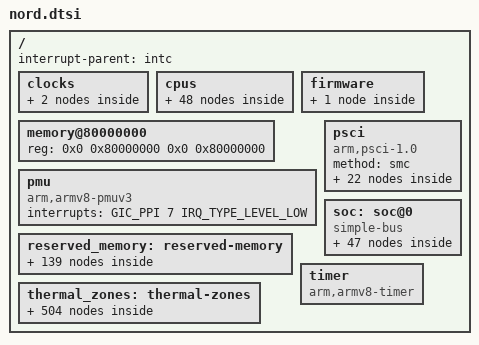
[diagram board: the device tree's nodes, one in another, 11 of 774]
// SPDX-License-Identifier: BSD-3-Clause
/*
 * Copyright (c) Qualcomm Technologies, Inc. and/or its subsidiaries.
 */

#include <dt-bindings/interrupt-controller/arm-gic.h>
#include <dt-bindings/mailbox/qcom-ipcc.h>
#include <dt-bindings/gpio/gpio.h>
/ {

	interrupt-parent = <&intc>;

	#address-cells = <2>;
	#size-cells = <2>;

	clocks {
		xo_board_clk: xo-board-clk {
			compatible = "fixed-clock";
			clock-frequency = <19200000>;
			#clock-cells = <0>;
		};

		sleep_clk: sleep-clk {
			compatible = "fixed-clock";
			clock-frequency = <32768>;
			#clock-cells = <0>;
		};
	};

	cpus {
		#address-cells = <2>;
		#size-cells = <0>;

		cpu0: cpu@0 {
			device_type = "cpu";
			compatible = "arm,armv8";
			reg = <0x0 0x0>;
			enable-method = "psci";
			power-domains = <&cpu_pd0>;
			power-domain-names = "psci";
			next-level-cache = <&l2_0>;
			clocks = <&cpu_perf 0>;
			l2_0: l2-cache {
				compatible = "cache";
				cache-level = <2>;
				cache-unified;
			};

		};

		cpu1: cpu@100 {
			device_type = "cpu";
			compatible = "arm,armv8";
			reg = <0x0 0x100>;
			enable-method = "psci";
			power-domains = <&cpu_pd1>;
			power-domain-names = "psci";
			next-level-cache = <&l2_0>;
			clocks = <&cpu_perf 0>;
		};

		cpu2: cpu@200 {
			device_type = "cpu";
			compatible = "arm,armv8";
			reg = <0x0 0x200>;
			enable-method = "psci";
			power-domains = <&cpu_pd2>;
			power-domain-names = "psci";
			next-level-cache = <&l2_0>;
			clocks = <&cpu_perf 0>;
		};

		cpu3: cpu@300 {
			device_type = "cpu";
			compatible = "arm,armv8";
			reg = <0x0 0x300>;
			enable-method = "psci";
			power-domains = <&cpu_pd3>;
			power-domain-names = "psci";
			next-level-cache = <&l2_0>;
			clocks = <&cpu_perf 0>;
		};

		cpu4: cpu@400 {
			device_type = "cpu";
			compatible = "arm,armv8";
			reg = <0x0 0x400>;
			enable-method = "psci";
			power-domains = <&cpu_pd4>;
			power-domain-names = "psci";
			next-level-cache = <&l2_0>;
			clocks = <&cpu_perf 0>;
		};

		cpu5: cpu@500 {
			device_type = "cpu";
			compatible = "arm,armv8";
			reg = <0x0 0x500>;
			enable-method = "psci";
			power-domains = <&cpu_pd5>;
			power-domain-names = "psci";
			next-level-cache = <&l2_0>;
			clocks = <&cpu_perf 0>;
		};

		cpu6: cpu@10000 {
			device_type = "cpu";
			compatible = "arm,armv8";
			reg = <0x0 0x10000>;
			power-domains = <&cpu_pd6>;
			power-domain-names = "psci";
			enable-method = "psci";
			next-level-cache = <&l2_10000>;
			clocks = <&cpu_perf 1>;
			l2_10000: l2-cache {
				compatible = "cache";
				cache-level = <2>;
				cache-unified;
			};
		};

		cpu7: cpu@10100 {
			device_type = "cpu";
			compatible = "arm,armv8";
			reg = <0x0 0x10100>;
			enable-method = "psci";
			power-domains = <&cpu_pd7>;
			power-domain-names = "psci";
			next-level-cache = <&l2_10000>;
			clocks = <&cpu_perf 1>;
		};

		cpu8: cpu@10200 {
			device_type = "cpu";
			compatible = "arm,armv8";
			reg = <0x0 0x10200>;
			enable-method = "psci";
			power-domains = <&cpu_pd8>;
			power-domain-names = "psci";
			next-level-cache = <&l2_10000>;
			clocks = <&cpu_perf 1>;
		};

		cpu9: cpu@10300 {
			device_type = "cpu";
			compatible = "arm,armv8";
			reg = <0x0 0x10300>;
			enable-method = "psci";
			power-domains = <&cpu_pd9>;
			power-domain-names = "psci";
			next-level-cache = <&l2_10000>;
			clocks = <&cpu_perf 1>;
		};

		cpu10: cpu@10400 {
			device_type = "cpu";
			compatible = "arm,armv8";
			reg = <0x0 0x10400>;
			enable-method = "psci";
			power-domains = <&cpu_pd10>;
			power-domain-names = "psci";
			next-level-cache = <&l2_10000>;
			clocks = <&cpu_perf 1>;
		};

		cpu11: cpu@10500 {
			device_type = "cpu";
			compatible = "arm,armv8";
			reg = <0x0 0x10500>;
			enable-method = "psci";
			power-domains = <&cpu_pd11>;
			power-domain-names = "psci";
			next-level-cache = <&l2_10000>;
			clocks = <&cpu_perf 1>;
		};

		cpu12: cpu@20000 {
			device_type = "cpu";
			compatible = "arm,armv8";
			reg = <0x0 0x20000>;
			enable-method = "psci";
			power-domains = <&cpu_pd12>;
			power-domain-names = "psci";
			next-level-cache = <&l2_20000>;
			clocks = <&cpu_perf 2>;
			l2_20000: l2-cache {
				compatible = "cache";
				cache-level = <2>;
				cache-unified;
			};
		};

		cpu13: cpu@20100 {
			device_type = "cpu";
			compatible = "arm,armv8";
			reg = <0x0 0x20100>;
			enable-method = "psci";
			power-domains = <&cpu_pd13>;
			power-domain-names = "psci";
			next-level-cache = <&l2_20000>;
			clocks = <&cpu_perf 2>;
		};

		cpu14: cpu@20200 {
			device_type = "cpu";
			compatible = "arm,armv8";
			reg = <0x0 0x20200>;
			enable-method = "psci";
			power-domains = <&cpu_pd14>;
			power-domain-names = "psci";
			next-level-cache = <&l2_20000>;
			clocks = <&cpu_perf 2>;
		};

		cpu15: cpu@20300 {
			device_type = "cpu";
			compatible = "arm,armv8";
			reg = <0x0 0x20300>;
			enable-method = "psci";
			power-domains = <&cpu_pd15>;
			power-domain-names = "psci";
			next-level-cache = <&l2_20000>;
			clocks = <&cpu_perf 2>;
		};

		cpu16: cpu@20400 {
			device_type = "cpu";
			compatible = "arm,armv8";
			reg = <0x0 0x20400>;
			enable-method = "psci";
			power-domains = <&cpu_pd16>;
			power-domain-names = "psci";
			next-level-cache = <&l2_20000>;
			clocks = <&cpu_perf 2>;
		};

		cpu17: cpu@20500 {
			device_type = "cpu";
			compatible = "arm,armv8";
			reg = <0x0 0x20500>;
			enable-method = "psci";
			power-domains = <&cpu_pd17>;
			power-domain-names = "psci";
			next-level-cache = <&l2_20000>;
			clocks = <&cpu_perf 2>;
		};

		cpu-map {
			cluster0 {
				core0 {
					cpu = <&cpu0>;
				};

				core1 {
					cpu = <&cpu1>;
				};

				core2 {
					cpu = <&cpu2>;
				};

				core3 {
					cpu = <&cpu3>;
				};

				core4 {
					cpu = <&cpu4>;
				};

				core5 {
					cpu = <&cpu5>;
				};
			};

			cluster1 {
				core0 {
					cpu = <&cpu6>;
				};

				core1 {
					cpu = <&cpu7>;
				};

				core2 {
					cpu = <&cpu8>;
				};

				core3 {
					cpu = <&cpu9>;
				};

				core4 {
					cpu = <&cpu10>;
				};

				core5 {
					cpu = <&cpu11>;
				};
			};

			cluster2 {
				core0 {
					cpu = <&cpu12>;
				};

				core1 {
					cpu = <&cpu13>;
				};

				core2 {
					cpu = <&cpu14>;
				};

				core3 {
					cpu = <&cpu15>;
				};

				core4 {
					cpu = <&cpu16>;
				};

				core5 {
					cpu = <&cpu17>;
				};
			};
		};

		idle-states {
			entry-method = "psci";

			cpu_c4: cpu-sleep { /* C4 */
				compatible = "arm,idle-state";
				idle-state-name = "ret";
				arm,psci-suspend-param = <0x00000003>;
				entry-latency-us = <93>;
				exit-latency-us = <129>;
				min-residency-us = <560>;				
			};
		};

		domain-idle-states {
			cluster_pwr_dn: cluster-sleep-0 {
				compatible = "domain-idle-state";
				arm,psci-suspend-param = <0x01000053>;
				entry-latency-us = <2150>;
				exit-latency-us = <1983>;
				min-residency-us = <9144>;
			};

			domain_ss3: domain-sleep-0 {
				compatible = "domain-idle-state";
				arm,psci-suspend-param = <0x0200c353>;
				entry-latency-us = <2800>;
				exit-latency-us = <4400>;
				min-residency-us = <10150>;
			};
		};
	};

	firmware: firmware {
		scm {
			compatible = "qcom,scm-nord", "qcom,scm";
			qcom,dload-mode = <&tcsr 0x79000>;
		};
	};

	memory@80000000 {
		device_type = "memory";
		reg = <0x0 0x80000000 0x0 0x80000000>;
	};

	pmu {
		compatible = "arm,armv8-pmuv3";
		interrupts = <GIC_PPI 7 IRQ_TYPE_LEVEL_LOW>;
	};

	psci {
		compatible = "arm,psci-1.0";
		method = "smc";

		cpu_pd0: power-domain-cpu0 {
			#power-domain-cells = <0>;
			power-domains = <&cluster0_pd>;
			domain-idle-states = <&cpu_c4>;
		};

		cpu_pd1: power-domain-cpu1 {
			#power-domain-cells = <0>;
			power-domains = <&cluster0_pd>;
			domain-idle-states = <&cpu_c4>;
		};

		cpu_pd2: power-domain-cpu2 {
			#power-domain-cells = <0>;
			power-domains = <&cluster0_pd>;
			domain-idle-states = <&cpu_c4>;
		};

		cpu_pd3: power-domain-cpu3 {
			#power-domain-cells = <0>;
			power-domains = <&cluster0_pd>;
			domain-idle-states = <&cpu_c4>;
		};

		cpu_pd4: power-domain-cpu4 {
			#power-domain-cells = <0>;
			power-domains = <&cluster0_pd>;
			domain-idle-states = <&cpu_c4>;
		};

		cpu_pd5: power-domain-cpu5 {
			#power-domain-cells = <0>;
			power-domains = <&cluster0_pd>;
			domain-idle-states = <&cpu_c4>;
		};

		cpu_pd6: power-domain-cpu6 {
			#power-domain-cells = <0>;
			power-domains = <&cluster1_pd>;
			domain-idle-states = <&cpu_c4>;
		};

		cpu_pd7: power-domain-cpu7 {
			#power-domain-cells = <0>;
			power-domains = <&cluster1_pd>;
			domain-idle-states = <&cpu_c4>;
		};

		cpu_pd8: power-domain-cpu8 {
			#power-domain-cells = <0>;
			power-domains = <&cluster1_pd>;
			domain-idle-states = <&cpu_c4>;
		};

		cpu_pd9: power-domain-cpu9 {
			#power-domain-cells = <0>;
			power-domains = <&cluster1_pd>;
			domain-idle-states = <&cpu_c4>;
		};

		cpu_pd10: power-domain-cpu10 {
			#power-domain-cells = <0>;
			power-domains = <&cluster1_pd>;
			domain-idle-states = <&cpu_c4>;
		};

		cpu_pd11: power-domain-cpu11 {
			#power-domain-cells = <0>;
			power-domains = <&cluster1_pd>;
			domain-idle-states = <&cpu_c4>;
		};

		cpu_pd12: power-domain-cpu12 {
			#power-domain-cells = <0>;
			power-domains = <&cluster2_pd>;
			domain-idle-states = <&cpu_c4>;
		};

		cpu_pd13: power-domain-cpu13 {
			#power-domain-cells = <0>;
			power-domains = <&cluster2_pd>;
			domain-idle-states = <&cpu_c4>;
		};

		cpu_pd14: power-domain-cpu14 {
			#power-domain-cells = <0>;
			power-domains = <&cluster2_pd>;
			domain-idle-states = <&cpu_c4>;
		};

		cpu_pd15: power-domain-cpu15 {
			#power-domain-cells = <0>;
			power-domains = <&cluster2_pd>;
			domain-idle-states = <&cpu_c4>;
		};

		cpu_pd16: power-domain-cpu16 {
			#power-domain-cells = <0>;
			power-domains = <&cluster2_pd>;
			domain-idle-states = <&cpu_c4>;
		};

		cpu_pd17: power-domain-cpu17 {
			#power-domain-cells = <0>;
			power-domains = <&cluster2_pd>;
			domain-idle-states = <&cpu_c4>;
		};

		cluster0_pd: power-domain-cluster0 {
			#power-domain-cells = <0>;
			power-domains = <&system_pd>;
			domain-idle-states = <&cluster_pwr_dn>;
		};

		cluster1_pd: power-domain-cluster1 {
			#power-domain-cells = <0>;
			power-domains = <&system_pd>;
			domain-idle-states = <&cluster_pwr_dn>;
		};

		cluster2_pd: power-domain-cluster2 {
			#power-domain-cells = <0>;
			power-domains = <&system_pd>;
			domain-idle-states = <&cluster_pwr_dn>;
		};

		system_pd: power-domain-cluster3 {
			#power-domain-cells = <0>;
			domain-idle-states = <&domain_ss3>;
		};
	};

	reserved_memory: reserved-memory {
		#address-cells = <2>;
		#size-cells = <2>;
		ranges;

		cpucp_scandump_mem: cpucp_scandump_region@80000000 {
			no-map;
			reg = <0x0 0x80000000 0x0 0x800000>;
		};

		tme_sail_mem: tme_sail_region@81ff0000 {
			no-map;
			reg = <0x0 0x81ff0000 0x0 0x10000>;
		};

		tz_sail_mailbox_mem: tz_sail_mailbox_region@82000000 {
			no-map;
			reg = <0x0 0x82000000 0x0 0x8000>;
		};

		hlos_sail_mailbox_mem: hlos_sail_mailbox_region@82008000 {
			no-map;
			reg = <0x0 0x82008000 0x0 0x1f8000>;
		};

		sail_ota_mem: sail_ota_region@82200000 {
			no-map;
			reg = <0x0 0x82200000 0x0 0x5ff000>;
		};

		sail_vdt_mem: sail_vdt_region@827ff000 {
			no-map;
			reg = <0x0 0x827ff000 0x0 0x1000>;
		};

		gunyah_hyp_mem: gunyah_hyp_region@82800000 {
			no-map;
			reg = <0x0 0x82800000 0x0 0x2400000>;
		};

		deepsleep_mem: deepsleep_region@84c00000 {
			no-map;
			reg = <0x0 0x84c00000 0x0 0x800000>;
		};

		deepsleep_backup_mem: deepsleep_backup_region@86a00000 {
			no-map;
			reg = <0x0 0x86a00000 0x0 0x200000>;
		};

		soccp_fe_vm_0: soccp_fe_vm_0_region@86c00000 {
			no-map;
			reg = <0x0 0x86c00000 0x0 0xac000>;
		};

		soccp_fe_vm_1: soccp_fe_vm_1_region@86cac000 {
			no-map;
			reg = <0x0 0x86cac000 0x0 0x18d000>;
		};

		soccp_fe_vm_2: soccp_fe_vm_2_region@86e39000 {
			no-map;
			reg = <0x0 0x86e39000 0x0 0x1c7000>;
		};

		tme_crash_dump_mem: tme_crash_dump_region@87000000 {
			no-map;
			reg = <0x0 0x87000000 0x0 0xa0000>;
		};

		tme_log_mem: tme_log_region@87140000 {
			no-map;
			reg = <0x0 0x87140000 0x0 0x4000>;
		};

		aop_cmd_db_p_mem: aop_cmd_db_p_region@87148000 {
			compatible = "qcom,cmd-db";
			no-map;
			reg = <0x0 0x87148000 0x0 0x20000>;
		};

		nsp_sync_buffer_mem: nsp_sync_buffer_region@871ff000 {
			no-map;
			reg = <0x0 0x871ff000 0x0 0x1000>;
		};

		ddr_training_checksum_data_mem: ddr_training_checksum_data_region@87200000 {
			no-map;
			reg = <0x0 0x87200000 0x0 0x2000>;
		};

		xbl_dtlog_mem: xbl_dtlog_region@87202000 {
			no-map;
			reg = <0x0 0x87202000 0x0 0x60000>;
		};

		xbl_ramdump_mem: xbl_ramdump_region@87262000 {
			no-map;
			reg = <0x0 0x87262000 0x0 0x1c0000>;
		};

		uefi_log: uefi-log@87442000 {
			reg = <0x0 0x87442000 0x0 0x10000>;
			no-map;
		};

		secdata_apss_mem: secdata_apss_region@87452000 {
			no-map;
			reg = <0x0 0x87452000 0x0 0x1000>;
		};

		antireplay_emulation_mem: antireplay_emulation_region@87453000 {
			no-map;
			reg = <0x0 0x87453000 0x0 0x1000>;
		};

		soccp_sdi_mem: soccp_sdi_region@87454000 {
			no-map;
			reg = <0x0 0x87454000 0x0 0x40000>;
		};

		hyp_mem_database_mem: hyp_mem_database_region@87494000 {
			no-map;
			reg = <0x0 0x87494000 0x0 0x60000>;
		};

		pmic_mini_dump_mem: pmic_mini_dump_region@874f4000 {
			no-map;
			reg = <0x0 0x874f4000 0x0 0x80000>;
		};

		qup_fw_mem: qup_fw_region@87574000 {
			no-map;
			reg = <0x0 0x87574000 0x0 0x20000>;
		};

		softsku_mem: softsku_region@87594000 {
			no-map;
			reg = <0x0 0x87594000 0x0 0x9000>;
		};

		resource_scheduler_mem: resource_scheduler_region@8759d000 {
			no-map;
			reg = <0x0 0x8759d000 0x0 0x20000>;
		};

		pdp_ns_mem: pdp_ns_mem_region@87600000 {
			no-map;
			reg = <0x0 0x87600000 0x0 0x200000>;
		};

		tz_stat_mem: tz_stat_region@87a00000 {
			no-map;
			reg = <0x0 0x87a00000 0x0 0x100000>;
		};

		qdss_apps_mem: qdss_apps_region@87b00000 {
			no-map;
			reg = <0x0 0x87b00000 0x0 0x2000000>;
		};

		smem_mem: smem_region@89b00000 {
			compatible = "qcom,smem";
			no-map;
			reg = <0x0 0x89b00000 0x0 0x400000>;
			hwlocks = <&tcsr_mutex 3>;
		};

		global_sync_mem: global_sync_region@89f00000 {
			no-map;
			reg = <0x0 0x89f00000 0x0 0x400000>;
		};

		tzffi_mem: tzffi_region@8a300000 {
			compatible = "shared-dma-pool";
			reg = <0x0 0x8a300000 0x0 0x1400000>;
			no-map;
		};

		gunyah_md_mem: gunyah_md_region@8b700000 {
			no-map;
			reg = <0x0 0x8b700000 0x0 0x80000>;
		};

		flashless_qntm_tool_mem: flashless_qntm_tool_region@8b780000 {
			no-map;
			reg = <0x0 0x8b780000 0x0 0x182000>;
		};

		ipa_fw_mem: ipa_fw_region@8bb00000 {
			no-map;
			reg = <0x0 0x8bb00000 0x0 0x10000>;
		};

		ipa_gsi_mem: ipa_gsi_region@8bb10000 {
			no-map;
			reg = <0x0 0x8bb10000 0x0 0xa000>;
		};

		gpu_microcode_mem: gpu_microcode_region@8bb1a000 {
			no-map;
			reg = <0x0 0x8bb1a000 0x0 0x2000>;
		};

		gpu_microcode_2_mem: gpu_microcode_2_region@8bb1c000 {
			no-map;
			reg = <0x0 0x8bb1c000 0x0 0x2000>;
		};

		soccp_mem: soccp_region@8bc00000 {
			no-map;
			reg = <0x0 0x8bc00000 0x0 0x300000>;
		};

		cvp_mem: cvp_region@8d100000 {
			no-map;
			reg = <0x0 0x8d100000 0x0 0x800000>;
		};

		cdsp0_mem: cdsp0_region@8d900000 {
			no-map;
			reg = <0x0 0x8d900000 0x0 0x2300000>;
		};

		cdsp1_mem: cdsp1_region@8fc00000 {
			no-map;
			reg = <0x0 0x8fc00000 0x0 0x2300000>;
		};

		cdsp2_mem: cdsp2_region@91f00000 {
			no-map;
			reg = <0x0 0x91f00000 0x0 0x2300000>;
		};

		cdsp3_mem: cdsp3_region@94200000 {
			no-map;
			reg = <0x0 0x94200000 0x0 0x2300000>;
		};

		hpass_dsp0_mem: hpass_dsp0_region@96500000 {
			no-map;
			reg = <0x0 0x96500000 0x0 0x2800000>;
		};

		hpass_dsp1_mem: hpass_dsp1_region@98d00000 {
			no-map;
			reg = <0x0 0x98d00000 0x0 0x2800000>;
		};

		hpass_dsp2_mem: hpass_dsp2_region@9b500000 {
			no-map;
			reg = <0x0 0x9b500000 0x0 0x2800000>;
		};

		q6_cdsp0_dtb_mem: q6_cdsp0_dtb_region@9dd00000 {
			no-map;
			reg = <0x0 0x9dd00000 0x0 0x80000>;
		};

		q6_cdsp1_dtb_mem: q6_cdsp1_dtb_region@9dd80000 {
			no-map;
			reg = <0x0 0x9dd80000 0x0 0x80000>;
		};

		q6_cdsp2_dtb_mem: q6_cdsp2_dtb_region@9de00000 {
			no-map;
			reg = <0x0 0x9de00000 0x0 0x80000>;
		};

		q6_cdsp3_dtb_mem: q6_cdsp3_dtb_region@9de80000 {
			no-map;
			reg = <0x0 0x9de80000 0x0 0x80000>;
		};

		hpass_dsp0_dtb_mem: hpass_dsp0_dtb_region@9df00000 {
			no-map;
			reg = <0x0 0x9df00000 0x0 0x80000>;
		};

		hpass_dsp1_dtb_mem: hpass_dsp1_dtb_region@9df80000 {
			no-map;
			reg = <0x0 0x9df80000 0x0 0x80000>;
		};

		hpass_dsp2_dtb_mem: hpass_dsp2_dtb_region@9e000000 {
			no-map;
			reg = <0x0 0x9e000000 0x0 0x100000>;
		};

		camera_icp_1_mem: camera_icp_1_region@9e100000 {
			no-map;
			reg = <0x0 0x9e100000 0x0 0x800000>;
		};

		camera_icp_2_mem: camera_icp_2_region@9e900000 {
			no-map;
			reg = <0x0 0x9e900000 0x0 0x800000>;
		};

		camera_qup_1_mem: camera_qup_1_region@9f100000 {
			no-map;
			reg = <0x0 0x9f100000 0x0 0x200000>;
		};

		camera_qup_2_mem: camera_qup_2_region@9f300000 {
			no-map;
			reg = <0x0 0x9f300000 0x0 0x200000>;
		};

		video_mem: video_region@9f500000 {
			no-map;
			reg = <0x0 0x9f500000 0x0 0xc00000>;
		};

		pil_umd_reserved: mdt_load_region@a0100000 {
			no-map;
			reg = <0x0 0xa0100000 0x0 0x100000>;
		};

		mm_dspq: mm_dspq_region@ba200000 {
			no-map;
			reg = <0x0 0xba200000 0x0 0x200000>;
		};

		display_config_reserved: display_config_region@ba400000 {
			no-map;
			reg = <0x0 0xba400000 0x0 0xa00000>;
		};

		mm_calibration_data_mem: mm_calibration_data_region@bae00000 {
			no-map;
			reg = <0x0 0xbae00000 0x0 0x800000>;
		};

		audio_config_mem: audio_config_region@bb600000 {
			no-map;
			reg = <0x0 0xbb600000 0x0 0xa00000>;
		};

		dare_tz_mem: dare_tz_region@bc000000 {
			no-map;
			reg = <0x0 0xbc000000 0x0 0xa300000>;
		};

		hpass_rpc_remote_heap_mem: hpass_rpc_remote_heap_region@d4600000 {
			no-map;
			reg = <0x0 0xd4600000 0x0 0x800000>;
		};

		mdf_mem: mdf_region@d4e00000 {
			no-map;
			reg = <0x0 0xd4e00000 0x0 0x2000000>;
		};

		gearvm_mem: gearvm_region@d6e00000 {
			no-map;
			reg = <0x0 0xd6e00000 0x0 0x800000>;
		};

		shmem0: scmi-sram@d7600000 {
			compatible = "arm,scmi-shmem";
			reg = <0x0 0xd7600000 0x0 0x1000>;
			no-map;
		};

		shmem1: scmi-sram@d7601000 {
			compatible = "arm,scmi-shmem";
			reg = <0x0 0xd7601000 0x0 0x1000>;
			no-map;
		};

		shmem2: scmi-sram@d7602000 {
			compatible = "arm,scmi-shmem";
			reg = <0x0 0xd7602000 0x0 0x1000>;
			no-map;
		};

		shmem3: scmi-sram@d7603000 {
			compatible = "arm,scmi-shmem";
			reg = <0x0 0xd7603000 0x0 0x1000>;
			no-map;
		};

		shmem4: scmi-sram@d7604000 {
			compatible = "arm,scmi-shmem";
			reg = <0x0 0xd7604000 0x0 0x1000>;
			no-map;
		};

		shmem5: scmi-sram@d7605000 {
			compatible = "arm,scmi-shmem";
			reg = <0x0 0xd7605000 0x0 0x1000>;
			no-map;
		};

		shmem6: scmi-sram@d7606000 {
			compatible = "arm,scmi-shmem";
			reg = <0x0 0xd7606000 0x0 0x1000>;
			no-map;
		};

		shmem7: scmi-sram@d7607000 {
			compatible = "arm,scmi-shmem";
			reg = <0x0 0xd7607000 0x0 0x1000>;
			no-map;
		};

		shmem8: scmi-sram@d7608000 {
			compatible = "arm,scmi-shmem";
			reg = <0x0 0xd7608000 0x0 0x1000>;
			no-map;
		};

		shmem9: scmi-sram@d7609000 {
			compatible = "arm,scmi-shmem";
			reg = <0x0 0xd7609000 0x0 0x1000>;
			no-map;
		};

		shmem10: scmi-sram@d760a000 {
			compatible = "arm,scmi-shmem";
			reg = <0x0 0xd760a000 0x0 0x1000>;
			no-map;
		};

		shmem11: scmi-sram@d760b000 {
			compatible = "arm,scmi-shmem";
			reg = <0x0 0xd760b000 0x0 0x1000>;
			no-map;
		};

		shmem12: scmi-sram@d760c000 {
			compatible = "arm,scmi-shmem";
			reg = <0x0 0xd760c000 0x0 0x1000>;
			no-map;
		};

		shmem13: scmi-sram@d760d000 {
			compatible = "arm,scmi-shmem";
			reg = <0x0 0xd760d000 0x0 0x1000>;
			no-map;
		};

		shmem14: scmi-sram@d760e000 {
			compatible = "arm,scmi-shmem";
			reg = <0x0 0xd760e000 0x0 0x1000>;
			no-map;
		};

		shmem15: scmi-sram@d760f000 {
			compatible = "arm,scmi-shmem";
			reg = <0x0 0xd760f000 0x0 0x1000>;
			no-map;
		};

		shmem16: scmi-sram@d7610000 {
			compatible = "arm,scmi-shmem";
			reg = <0x0 0xd7610000 0x0 0x1000>;
			no-map;
		};

		shmem17: scmi-sram@d7611000 {
			compatible = "arm,scmi-shmem";
			reg = <0x0 0xd7611000 0x0 0x1000>;
			no-map;
		};

		shmem18: scmi-sram@d7612000 {
			compatible = "arm,scmi-shmem";
			reg = <0x0 0xd7612000 0x0 0x1000>;
			no-map;
		};

		shmem19: scmi-sram@d7613000 {
			compatible = "arm,scmi-shmem";
			reg = <0x0 0xd7613000 0x0 0x1000>;
			no-map;
		};

		shmem20: scmi-sram@d7614000 {
			compatible = "arm,scmi-shmem";
			reg = <0x0 0xd7614000 0x0 0x1000>;
			no-map;
		};

		shmem21: scmi-sram@d7615000 {
			compatible = "arm,scmi-shmem";
			reg = <0x0 0xd7615000 0x0 0x1000>;
			no-map;
		};

		shmem22: scmi-sram@d7616000 {
			compatible = "arm,scmi-shmem";
			reg = <0x0 0xd7616000 0x0 0x1000>;
			no-map;
		};

		shmem23: scmi-sram@d7617000 {
			compatible = "arm,scmi-shmem";
			reg = <0x0 0xd7617000 0x0 0x1000>;
			no-map;
		};

		shmem24: scmi-sram@d7618000 {
			compatible = "arm,scmi-shmem";
			reg = <0x0 0xd7618000 0x0 0x1000>;
			no-map;
		};

		shmem25: scmi-sram@d7619000 {
			compatible = "arm,scmi-shmem";
			reg = <0x0 0xd7619000 0x0 0x1000>;
			no-map;
		};

		shmem26: scmi-sram@d761a000 {
			compatible = "arm,scmi-shmem";
			reg = <0x0 0xd761a000 0x0 0x1000>;
			no-map;
		};

		shmem27: scmi-sram@d761b000 {
			compatible = "arm,scmi-shmem";
			reg = <0x0 0xd761b000 0x0 0x1000>;
			no-map;
		};

		shmem28: scmi-sram@d761c000 {
			compatible = "arm,scmi-shmem";
			reg = <0x0 0xd761c000 0x0 0x1000>;
			no-map;
		};

		shmem29: scmi-sram@d761d000 {
			compatible = "arm,scmi-shmem";
			reg = <0x0 0xd761d000 0x0 0x1000>;
			no-map;
		};

		shmem30: scmi-sram@d761e000 {
			compatible = "arm,scmi-shmem";
			reg = <0x0 0xd761e000 0x0 0x1000>;
			no-map;
		};

		shmem31: scmi-sram@d761f000 {
			compatible = "arm,scmi-shmem";
			reg = <0x0 0xd761f000 0x0 0x1000>;
			no-map;
		};

		shmem32: scmi-sram@d7620000 {
			compatible = "arm,scmi-shmem";
			reg = <0x0 0xd7620000 0x0 0x1000>;
			no-map;
		};

		shmem33: scmi-sram@d7621000 {
			compatible = "arm,scmi-shmem";
			reg = <0x0 0xd7621000 0x0 0x1000>;
			no-map;
		};

		shmem34: scmi-sram@d7622000 {
			compatible = "arm,scmi-shmem";
			reg = <0x0 0xd7622000 0x0 0x1000>;
			no-map;
		};

		shmem35: scmi-sram@d7623000 {
			compatible = "arm,scmi-shmem";
			reg = <0x0 0xd7623000 0x0 0x1000>;
			no-map;
		};

		shmem36: scmi-sram@d7624000 {
			compatible = "arm,scmi-shmem";
			reg = <0x0 0xd7624000 0x0 0x1000>;
			no-map;
		};

		shmem37: scmi-sram@d7625000 {
			compatible = "arm,scmi-shmem";
			reg = <0x0 0xd7625000 0x0 0x1000>;
			no-map;
		};

		shmem38: scmi-sram@d7626000 {
			compatible = "arm,scmi-shmem";
			reg = <0x0 0xd7626000 0x0 0x1000>;
			no-map;
		};

		shmem39: scmi-sram@d7627000 {
			compatible = "arm,scmi-shmem";
			reg = <0x0 0xd7627000 0x0 0x1000>;
			no-map;
		};

		shmem40: scmi-sram@d7628000 {
			compatible = "arm,scmi-shmem";
			reg = <0x0 0xd7628000 0x0 0x1000>;
			no-map;
		};

		shmem41: scmi-sram@d7629000 {
			compatible = "arm,scmi-shmem";
			reg = <0x0 0xd7629000 0x0 0x1000>;
			no-map;
		};

		shmem42: scmi-sram@d762a000 {
			compatible = "arm,scmi-shmem";
			reg = <0x0 0xd762a000 0x0 0x1000>;
			no-map;
		};

		shmem43: scmi-sram@d762b000 {
			compatible = "arm,scmi-shmem";
			reg = <0x0 0xd762b000 0x0 0x1000>;
			no-map;
		};

		shmem44: scmi-sram@d762c000 {
			compatible = "arm,scmi-shmem";
			reg = <0x0 0xd762c000 0x0 0x1000>;
			no-map;
		};

		shmem45: scmi-sram@d762d000 {
			compatible = "arm,scmi-shmem";
			reg = <0x0 0xd762d000 0x0 0x1000>;
			no-map;
		};

		shmem46: scmi-sram@d762e000 {
			compatible = "arm,scmi-shmem";
			reg = <0x0 0xd762e000 0x0 0x1000>;
			no-map;
		};

		shmem47: scmi-sram@d762f000 {
			compatible = "arm,scmi-shmem";
			reg = <0x0 0xd762f000 0x0 0x1000>;
			no-map;
		};

		shmem48: scmi-sram@d7630000 {
			compatible = "arm,scmi-shmem";
			reg = <0x0 0xd7630000 0x0 0x1000>;
			no-map;
		};

		shmem49: scmi-sram@d7631000 {
			compatible = "arm,scmi-shmem";
			reg = <0x0 0xd7631000 0x0 0x1000>;
			no-map;
		};

		shmem50: scmi-sram@d7632000 {
			compatible = "arm,scmi-shmem";
			reg = <0x0 0xd7632000 0x0 0x1000>;
			no-map;
		};

		shmem51: scmi-sram@d7633000 {
			compatible = "arm,scmi-shmem";
			reg = <0x0 0xd7633000 0x0 0x1000>;
			no-map;
		};

		shmem52: scmi-sram@d7634000 {
			compatible = "arm,scmi-shmem";
			reg = <0x0 0xd7634000 0x0 0x1000>;
			no-map;
		};

		shmem53: scmi-sram@d7635000 {
			compatible = "arm,scmi-shmem";
			reg = <0x0 0xd7635000 0x0 0x1000>;
			no-map;
		};

		shmem54: scmi-sram@d7636000 {
			compatible = "arm,scmi-shmem";
			reg = <0x0 0xd7636000 0x0 0x1000>;
			no-map;
		};

		shmem55: scmi-sram@d7637000 {
			compatible = "arm,scmi-shmem";
			reg = <0x0 0xd7637000 0x0 0x1000>;
			no-map;
		};

		shmem56: scmi-sram@d7638000 {
			compatible = "arm,scmi-shmem";
			reg = <0x0 0xd7638000 0x0 0x1000>;
			no-map;
		};

		shmem57: scmi-sram@d7639000 {
			compatible = "arm,scmi-shmem";
			reg = <0x0 0xd7639000 0x0 0x1000>;
			no-map;
		};

		shmem58: scmi-sram@d763a000 {
			compatible = "arm,scmi-shmem";
			reg = <0x0 0xd763a000 0x0 0x1000>;
			no-map;
		};

		shmem59: scmi-sram@d763b000 {
			compatible = "arm,scmi-shmem";
			reg = <0x0 0xd763b000 0x0 0x1000>;
			no-map;
		};

		shmem60: scmi-sram@d763c000 {
			compatible = "arm,scmi-shmem";
			reg = <0x0 0xd763c000 0x0 0x1000>;
			no-map;
		};

		shmem61: scmi-sram@d763d000 {
			compatible = "arm,scmi-shmem";
			reg = <0x0 0xd763d000 0x0 0x1000>;
			no-map;
		};

		shmem62: scmi-sram@d763e000 {
			compatible = "arm,scmi-shmem";
			reg = <0x0 0xd763e000 0x0 0x1000>;
			no-map;
		};

		shmem63: scmi-sram@d763f000 {
			compatible = "arm,scmi-shmem";
			reg = <0x0 0xd763f000 0x0 0x1000>;
			no-map;
		};

		gearvm_logs_mem: gearvm_logs_region@d77d0000 {
			no-map;
			reg = <0x0 0xd77d0000 0x0 0x20000>;
		};

		gearvm_shared_mem: gearvm_shared_region@d7650000 {
			no-map;
			reg = <0x0 0xd7650000 0x0 0x1b0000>;
		};

		sail_p_mem: sail_p_region@8c0000000 {
			no-map;
			reg = <0x8 0xc0000000 0x0 0x8000000>;
		};

		reserved_mem2: reserved_region@8c8000000 {
			no-map;
			reg = <0x8 0xc8000000 0x0 0x18000000>;
		};

		dump_mem: mem-dump-region {
			alloc-ranges = <0x0 0x00000000 0x0 0xffffffff>;
			size = <0x0 0x79b0000>;
		};
	};

	soc: soc@0 {
		compatible = "simple-bus";
		#address-cells = <2>;
		#size-cells = <2>;
		ranges = <0 0 0 0 0x10 0>;

		qupv3_id_2: geniqup@8c0000 {
			compatible = "qcom,nord-auto-geni-se-qup","qcom,sa8255p-geni-se-qup";
			reg = <0x0 0x8c0000 0x0 0x2000>;
			#address-cells = <2>;
			#size-cells = <2>;
			iommus = <&apps_smmu_0 0x15a3 0x0>;
			ranges;

			uart15: serial@884000 {
				compatible = "qcom,nord-auto-geni-debug-uart","qcom,sa8255p-geni-debug-uart";
				reg = <0x0 0x884000 0x0 0x4000>;
				interrupts = <GIC_SPI 583 IRQ_TYPE_LEVEL_HIGH>;
				power-domains = <&scmi11_pd 15>, <&scmi11_dvfs 15>;
				power-domain-names = "power", "perf";
				status = "disabled";
			};

			uart17: serial@88c000 {
				compatible = "qcom,nord-auto-geni-uart","qcom,sa8255p-geni-uart";
				reg = <0x0 0x88c000 0x0 0x4000>;
				interrupts = <GIC_SPI 585 IRQ_TYPE_LEVEL_HIGH>;
				power-domains = <&scmi11_pd 17>, <&scmi11_dvfs 17>;
				power-domain-names = "power", "perf";
				qcom,wakeup-byte = <0xfd>;
				status = "disabled";
			};
		};

		qupv3_id_0: geniqup@9c0000 {
			compatible = "qcom,nord-auto-geni-se-qup","qcom,sa8255p-geni-se-qup";
			reg = <0x0 0x9c0000 0x0 0x2000>;
			#address-cells = <2>;
			#size-cells = <2>;
			iommus = <&apps_smmu_2 0x1003 0x0>;
			ranges;

			uart3: serial@98c000 {
				compatible = "qcom,nord-auto-geni-uart","qcom,sa8255p-geni-uart";
				reg = <0x0 0x98c000 0x0 0x4000>;
				interrupts = <GIC_SPI 515 IRQ_TYPE_LEVEL_HIGH>;
				power-domains = <&scmi11_pd 3>, <&scmi11_dvfs 3>;
				power-domain-names = "power", "perf";
				qcom,wakeup-byte = <0xfd>;
				status = "disabled";
			};

			uart0: serial@980000 {
				compatible = "qcom,nord-auto-geni-uart","qcom,sa8255p-geni-uart";
				reg = <0x0 0x980000 0x0 0x4000>;
				interrupts = <GIC_SPI 314 IRQ_TYPE_LEVEL_HIGH>;
				power-domains = <&scmi11_pd 0>, <&scmi11_dvfs 0>;
				power-domain-names = "power", "perf";
				status = "disabled";
			};

			uart4: serial@990000 {
				compatible = "qcom,nord-auto-geni-uart","qcom,sa8255p-geni-uart";
				reg = <0x0 0x990000 0x0 0x4000>;
				interrupts = <GIC_SPI 516 IRQ_TYPE_LEVEL_HIGH>;
				power-domains = <&scmi11_pd 4>, <&scmi11_dvfs 4>;
				power-domain-names = "power", "perf";
				status = "disabled";
			};

			uart5: serial@994000 {
				compatible = "qcom,nord-auto-geni-uart","qcom,sa8255p-geni-uart";
				reg = <0x0 0x994000 0x0 0x4000>;
				interrupts = <GIC_SPI 517 IRQ_TYPE_LEVEL_HIGH>;
				power-domains = <&scmi11_pd 5>, <&scmi11_dvfs 5>;
				power-domain-names = "power", "perf";
				status = "disabled";
			};
		};

		qupv3_id_1: geniqup@ac0000 {
			compatible = "qcom,nord-auto-geni-se-qup","qcom,sa8255p-geni-se-qup";
			reg = <0x0 0xac0000 0x0 0x2000>;
			#address-cells = <2>;
			#size-cells = <2>;
			iommus = <&apps_smmu_2 0x1043 0x0>;
			ranges;

			uart9: serial@a88000 {
				compatible = "qcom,nord-auto-geni-uart","qcom,sa8255p-geni-uart";
				reg = <0x0 0xa88000 0x0 0x4000>;
				interrupts = <GIC_SPI 355 IRQ_TYPE_LEVEL_HIGH>;
				power-domains = <&scmi11_pd 9>, <&scmi11_dvfs 9>;
				power-domain-names = "power", "perf";
				status = "disabled";
			};

			uart10: serial@a8c000 {
				compatible = "qcom,nord-auto-geni-uart","qcom,sa8255p-geni-uart";
				reg = <0x0 0xa8c000 0x0 0x4000>;
				interrupts = <GIC_SPI 356 IRQ_TYPE_LEVEL_HIGH>;
				power-domains = <&scmi11_pd 10>, <&scmi11_dvfs 10>;
				power-domain-names = "power", "perf";
				status = "disabled";
			};

			uart12: serial@a94000 {
				compatible = "qcom,nord-auto-geni-uart","qcom,sa8255p-geni-uart";
				reg = <0x0 0xa94000 0x0 0x4000>;
				interrupts = <GIC_SPI 358 IRQ_TYPE_LEVEL_HIGH>;
				power-domains = <&scmi11_pd 12>, <&scmi11_dvfs 12>;
				power-domain-names = "power", "perf";
				qcom,wakeup-byte = <0xfd>;
				status = "disabled";
			};
		};

		tcsr_mutex: hwlock@1f40000 {
			compatible = "qcom,tcsr-mutex";
			reg = <0x0 0x01f40000 0x0 0x20000>;
			#hwlock-cells = <1>;
		};

		tcsr: syscon@1f60000 {
			compatible = "qcom,nord-tcsr", "syscon";
			reg = <0x0 0x1f60000 0x0 0xa0000>;
		};

		tsens0: thermal-sensor@c22c000 {
			compatible = "qcom,nord-tsens", "qcom,tsens-v2";
			reg = <0x0 0x0c22c000 0x0 0x1ff>,
			      <0x0 0x0c222000 0x0 0x8>;
			interrupts = <GIC_SPI 771 IRQ_TYPE_LEVEL_HIGH>,
				     <GIC_SPI 484 IRQ_TYPE_LEVEL_HIGH>;
			#qcom,sensors = <16>;
			interrupt-names = "uplow", "critical";
			#thermal-sensor-cells = <1>;
		};

		tsens1: thermal-sensor@c22d000 {
			compatible = "qcom,nord-tsens", "qcom,tsens-v2";
			reg = <0x0 0x0c22d000 0x0 0x1ff>,
			      <0x0 0x0c223000 0x0 0x8>;
			interrupts = <GIC_SPI 772 IRQ_TYPE_LEVEL_HIGH>,
				     <GIC_SPI 485 IRQ_TYPE_LEVEL_HIGH>;
			#qcom,sensors = <16>;
			interrupt-names = "uplow", "critical";
			#thermal-sensor-cells = <1>;
		};

		tsens2: thermal-sensor@c22e000 {
			compatible = "qcom,nord-tsens", "qcom,tsens-v2";
			reg = <0x0 0x0c22e000 0x0 0x1ff>,
			      <0x0 0x0c224000 0x0 0x8>;
			interrupts = <GIC_SPI 773 IRQ_TYPE_LEVEL_HIGH>,
				     <GIC_SPI 486 IRQ_TYPE_LEVEL_HIGH>;
			#qcom,sensors = <16>;
			interrupt-names = "uplow", "critical";
			#thermal-sensor-cells = <1>;
		};

		tsens3: thermal-sensor@c22f000 {
			compatible = "qcom,nord-tsens", "qcom,tsens-v2";
			reg = <0x0 0x0c22f000 0x0 0x1ff>,
			      <0x0 0x0c225000 0x0 0x8>;
			interrupts = <GIC_SPI 774 IRQ_TYPE_LEVEL_HIGH>,
				     <GIC_SPI 487 IRQ_TYPE_LEVEL_HIGH>;
			#qcom,sensors = <16>;
			interrupt-names = "uplow", "critical";
			#thermal-sensor-cells = <1>;
		};

		tsens4: thermal-sensor@c230000 {
			compatible = "qcom,nord-tsens", "qcom,tsens-v2";
			reg = <0x0 0x0c230000 0x0 0x1ff>,
			      <0x0 0x0c226000 0x0 0x8>;
			interrupts = <GIC_SPI 775 IRQ_TYPE_LEVEL_HIGH>,
				     <GIC_SPI 399 IRQ_TYPE_LEVEL_HIGH>;
			#qcom,sensors = <16>;
			interrupt-names = "uplow", "critical";
			#thermal-sensor-cells = <1>;
		};

		tsens5: thermal-sensor@c231000 {
			compatible = "qcom,nord-tsens", "qcom,tsens-v2";
			reg = <0x0 0x0c231000 0x0 0x1ff>,
			      <0x0 0x0c227000 0x0 0x8>;
			interrupts = <GIC_SPI 776 IRQ_TYPE_LEVEL_HIGH>,
				     <GIC_SPI 400 IRQ_TYPE_LEVEL_HIGH>;
			#qcom,sensors = <16>;
			interrupt-names = "uplow", "critical";
			#thermal-sensor-cells = <1>;
		};

		tsens6: thermal-sensor@c232000 {
			compatible = "qcom,nord-tsens", "qcom,tsens-v2";
			reg = <0x0 0x0c232000 0x0 0x1ff>,
			      <0x0 0x0c228000 0x0 0x8>;
			interrupts = <GIC_SPI 777 IRQ_TYPE_LEVEL_HIGH>,
				     <GIC_SPI 401 IRQ_TYPE_LEVEL_HIGH>;
			#qcom,sensors = <16>;
			interrupt-names = "uplow", "critical";
			#thermal-sensor-cells = <1>;
		};

		tsens7: thermal-sensor@c233000 {
			compatible = "qcom,nord-tsens", "qcom,tsens-v2";
			reg = <0x0 0x0c233000 0x0 0x1ff>,
			      <0x0 0x0c229000 0x0 0x8>;
			interrupts = <GIC_SPI 778 IRQ_TYPE_LEVEL_HIGH>,
				     <GIC_SPI 402 IRQ_TYPE_LEVEL_HIGH>;
			#qcom,sensors = <16>;
			interrupt-names = "uplow", "critical";
			#thermal-sensor-cells = <1>;
		};

		tlmm: pinctrl@f000000 {
			compatible = "qcom,nord-tlmm";
			reg = <0x0 0x0f000000 0x0 0x1000000>;
			interrupts = <GIC_SPI 208 IRQ_TYPE_LEVEL_HIGH>;
			gpio-controller;
			#gpio-cells = <2>;
			interrupt-controller;
			#interrupt-cells = <2>;
			gpio-ranges = <&tlmm 0 0 181>;
			wakeup-parent = <&pdc>;
		};

		intc: interrupt-controller@17000000 {
			compatible = "arm,gic-v3";
			reg = <0x0 0x17000000 0x0 0x10000>,     /* GICD */
			      <0x0 0x17080000 0x0 0x480000>;    /* GICR * 18 */
			interrupt-controller;
			#address-cells = <2>;
			#size-cells = <2>;
			#interrupt-cells = <3>;
			interrupts = <GIC_PPI 9 IRQ_TYPE_LEVEL_HIGH>;
			#redistributor-regions = <1>;
			redistributor-stride = <0x0 0x40000>;
			ranges;

			gic_its: msi-controller@17040000 {
				compatible = "arm,gic-v3-its";
				reg = <0x0 0x17040000 0x0 0x40000>;
				msi-controller;
				#msi-cells = <1>;
			};
		};

		pdc: interrupt-controller@b220000 {
			compatible = "qcom,nord-pdc", "qcom,pdc";
			reg = <0x0 0xb220000 0x0 0x10000>;
			qcom,pdc-ranges = <0 745 43>, <67 543 31>, <98 609 32>,
					  <130 717 12>, <142 251 5>, <147 796 16>;
			#interrupt-cells = <2>;
			interrupt-parent = <&intc>;
			interrupt-controller;
		};

		memtimer: timer@17810000 {
			compatible = "arm,armv7-timer-mem";
			reg = <0x0 0x17810000 0x0 0x1000>;
			ranges = <0x0 0x0 0x0 0x20000000>;
			#address-cells = <1>;
			#size-cells = <1>;

			frame@17811000 {
				reg = <0x17811000 0x1000>,
				      <0x17812000 0x1000>;
				interrupts = <GIC_SPI 38 IRQ_TYPE_LEVEL_HIGH>,
					     <GIC_SPI 31 IRQ_TYPE_LEVEL_HIGH>;
				frame-number = <0>;
			};

			frame@17813000 {
				reg = <0x17813000 0x1000>;
				interrupts = <GIC_SPI 39 IRQ_TYPE_LEVEL_HIGH>;
				frame-number = <1>;
				status = "disabled";
			};

			frame@17815000 {
				reg = <0x17815000 0x1000>;
				interrupts = <GIC_SPI 40 IRQ_TYPE_LEVEL_HIGH>;
				frame-number = <2>;
				status = "disabled";
			};

			frame@17817000 {
				reg = <0x17817000 0x1000>;
				interrupts = <GIC_SPI 41 IRQ_TYPE_LEVEL_HIGH>;
				frame-number = <3>;
				status = "disabled";
			};

			frame@17819000 {
				reg = <0x17819000 0x1000>;
				interrupts = <GIC_SPI 42 IRQ_TYPE_LEVEL_HIGH>;
				frame-number = <4>;
				status = "disabled";
			};

			frame@1781b000 {
				reg = <0x1781b000 0x1000>;
				interrupts = <GIC_SPI 43 IRQ_TYPE_LEVEL_HIGH>;
				frame-number = <5>;
				status = "disabled";
			};

			frame@1781d000 {
				reg = <0x1781d000 0x1000>;
				interrupts = <GIC_SPI 44 IRQ_TYPE_LEVEL_HIGH>;
				frame-number = <6>;
				status = "disabled";
			};
		};

		watchdog@17826000 {
			compatible = "qcom,kpss-wdt";
			reg = <0x0 0x17826000 0x0 0x1000>;
			clocks = <&sleep_clk>;
			interrupts = <GIC_ESPI 848 IRQ_TYPE_EDGE_RISING>;
		};


		ipcc0: mailbox@9007000 {
			compatible = "qcom,nord-ipcc", "qcom,ipcc";
			reg = <0x0 0x9007000 0x0 0x1000>;
			interrupts = <GIC_SPI 247 IRQ_TYPE_LEVEL_HIGH>;
			interrupt-controller;
			#interrupt-cells = <3>;
			#mbox-cells = <2>;
		};

		ipcc1: mailbox@90c5000 {
			compatible = "qcom,nord-ipcc", "qcom,ipcc";
			reg = <0x0 0x90c5000 0x0 0x1000>;
			interrupts = <GIC_SPI 230 IRQ_TYPE_LEVEL_HIGH>;
			interrupt-controller;
			#interrupt-cells = <3>;
			#mbox-cells = <2>;
		};

		ipcc2: mailbox@9185000 {
			compatible = "qcom,nord-ipcc", "qcom,ipcc";
			reg = <0x0 0x9185000 0x0 0x1000>;
			interrupts = <GIC_SPI 231 IRQ_TYPE_LEVEL_HIGH>;
			interrupt-controller;
			#interrupt-cells = <3>;
			#mbox-cells = <2>;
		};

		apps_smmu_0: iommu@15a00000 {
			compatible = "qcom,nord-smmu-500", "qcom,smmu-500", "arm,mmu-500";
			reg = <0x0 0x15a00000 0x0 0x100000>;
			#iommu-cells = <2>;
			#global-interrupts = <1>;
			dma-coherent;
			interrupts =	<GIC_SPI 886 IRQ_TYPE_LEVEL_HIGH>,
					<GIC_ESPI 32 IRQ_TYPE_LEVEL_HIGH>,
					<GIC_ESPI 33 IRQ_TYPE_LEVEL_HIGH>,
					<GIC_ESPI 34 IRQ_TYPE_LEVEL_HIGH>,
					<GIC_ESPI 35 IRQ_TYPE_LEVEL_HIGH>,
					<GIC_ESPI 36 IRQ_TYPE_LEVEL_HIGH>,
					<GIC_ESPI 37 IRQ_TYPE_LEVEL_HIGH>,
					<GIC_ESPI 38 IRQ_TYPE_LEVEL_HIGH>,
					<GIC_ESPI 39 IRQ_TYPE_LEVEL_HIGH>,
					<GIC_ESPI 40 IRQ_TYPE_LEVEL_HIGH>,
					<GIC_ESPI 41 IRQ_TYPE_LEVEL_HIGH>,
					<GIC_ESPI 42 IRQ_TYPE_LEVEL_HIGH>,
					<GIC_ESPI 43 IRQ_TYPE_LEVEL_HIGH>,
					<GIC_ESPI 44 IRQ_TYPE_LEVEL_HIGH>,
					<GIC_ESPI 45 IRQ_TYPE_LEVEL_HIGH>,
					<GIC_ESPI 46 IRQ_TYPE_LEVEL_HIGH>,
					<GIC_ESPI 47 IRQ_TYPE_LEVEL_HIGH>,
					<GIC_ESPI 48 IRQ_TYPE_LEVEL_HIGH>,
					<GIC_ESPI 49 IRQ_TYPE_LEVEL_HIGH>,
					<GIC_ESPI 50 IRQ_TYPE_LEVEL_HIGH>,
					<GIC_ESPI 51 IRQ_TYPE_LEVEL_HIGH>,
					<GIC_ESPI 52 IRQ_TYPE_LEVEL_HIGH>,
					<GIC_ESPI 53 IRQ_TYPE_LEVEL_HIGH>,
					<GIC_ESPI 54 IRQ_TYPE_LEVEL_HIGH>,
					<GIC_ESPI 55 IRQ_TYPE_LEVEL_HIGH>,
					<GIC_ESPI 56 IRQ_TYPE_LEVEL_HIGH>,
					<GIC_ESPI 57 IRQ_TYPE_LEVEL_HIGH>,
					<GIC_ESPI 58 IRQ_TYPE_LEVEL_HIGH>,
					<GIC_ESPI 59 IRQ_TYPE_LEVEL_HIGH>,
					<GIC_ESPI 60 IRQ_TYPE_LEVEL_HIGH>,
					<GIC_ESPI 61 IRQ_TYPE_LEVEL_HIGH>,
					<GIC_ESPI 62 IRQ_TYPE_LEVEL_HIGH>,
					<GIC_ESPI 63 IRQ_TYPE_LEVEL_HIGH>,
					<GIC_ESPI 64 IRQ_TYPE_LEVEL_HIGH>,
					<GIC_ESPI 65 IRQ_TYPE_LEVEL_HIGH>,
					<GIC_ESPI 66 IRQ_TYPE_LEVEL_HIGH>,
					<GIC_ESPI 67 IRQ_TYPE_LEVEL_HIGH>,
					<GIC_ESPI 68 IRQ_TYPE_LEVEL_HIGH>,
					<GIC_ESPI 69 IRQ_TYPE_LEVEL_HIGH>,
					<GIC_ESPI 70 IRQ_TYPE_LEVEL_HIGH>,
					<GIC_ESPI 71 IRQ_TYPE_LEVEL_HIGH>,
					<GIC_ESPI 72 IRQ_TYPE_LEVEL_HIGH>,
					<GIC_ESPI 73 IRQ_TYPE_LEVEL_HIGH>,
					<GIC_ESPI 74 IRQ_TYPE_LEVEL_HIGH>,
					<GIC_ESPI 75 IRQ_TYPE_LEVEL_HIGH>,
					<GIC_ESPI 76 IRQ_TYPE_LEVEL_HIGH>,
					<GIC_ESPI 77 IRQ_TYPE_LEVEL_HIGH>,
					<GIC_ESPI 78 IRQ_TYPE_LEVEL_HIGH>,
					<GIC_ESPI 79 IRQ_TYPE_LEVEL_HIGH>,
					<GIC_ESPI 80 IRQ_TYPE_LEVEL_HIGH>,
					<GIC_ESPI 81 IRQ_TYPE_LEVEL_HIGH>,
					<GIC_ESPI 82 IRQ_TYPE_LEVEL_HIGH>,
					<GIC_ESPI 83 IRQ_TYPE_LEVEL_HIGH>,
					<GIC_ESPI 84 IRQ_TYPE_LEVEL_HIGH>,
					<GIC_ESPI 85 IRQ_TYPE_LEVEL_HIGH>,
					<GIC_ESPI 86 IRQ_TYPE_LEVEL_HIGH>,
					<GIC_ESPI 87 IRQ_TYPE_LEVEL_HIGH>,
					<GIC_ESPI 88 IRQ_TYPE_LEVEL_HIGH>,
					<GIC_ESPI 89 IRQ_TYPE_LEVEL_HIGH>,
					<GIC_ESPI 90 IRQ_TYPE_LEVEL_HIGH>,
					<GIC_ESPI 91 IRQ_TYPE_LEVEL_HIGH>,
					<GIC_ESPI 92 IRQ_TYPE_LEVEL_HIGH>,
					<GIC_ESPI 93 IRQ_TYPE_LEVEL_HIGH>,
					<GIC_ESPI 94 IRQ_TYPE_LEVEL_HIGH>,
					<GIC_ESPI 95 IRQ_TYPE_LEVEL_HIGH>,
					<GIC_ESPI 96 IRQ_TYPE_LEVEL_HIGH>,
					<GIC_ESPI 97 IRQ_TYPE_LEVEL_HIGH>,
					<GIC_ESPI 98 IRQ_TYPE_LEVEL_HIGH>,
					<GIC_ESPI 99 IRQ_TYPE_LEVEL_HIGH>,
					<GIC_ESPI 100 IRQ_TYPE_LEVEL_HIGH>,
					<GIC_ESPI 101 IRQ_TYPE_LEVEL_HIGH>,
					<GIC_ESPI 102 IRQ_TYPE_LEVEL_HIGH>,
					<GIC_ESPI 103 IRQ_TYPE_LEVEL_HIGH>,
					<GIC_ESPI 104 IRQ_TYPE_LEVEL_HIGH>,
					<GIC_ESPI 105 IRQ_TYPE_LEVEL_HIGH>,
					<GIC_ESPI 106 IRQ_TYPE_LEVEL_HIGH>,
					<GIC_ESPI 107 IRQ_TYPE_LEVEL_HIGH>,
					<GIC_ESPI 108 IRQ_TYPE_LEVEL_HIGH>,
					<GIC_ESPI 109 IRQ_TYPE_LEVEL_HIGH>,
					<GIC_ESPI 110 IRQ_TYPE_LEVEL_HIGH>,
					<GIC_ESPI 111 IRQ_TYPE_LEVEL_HIGH>,
					<GIC_ESPI 112 IRQ_TYPE_LEVEL_HIGH>,
					<GIC_ESPI 113 IRQ_TYPE_LEVEL_HIGH>,
					<GIC_ESPI 114 IRQ_TYPE_LEVEL_HIGH>,
					<GIC_ESPI 115 IRQ_TYPE_LEVEL_HIGH>,
					<GIC_ESPI 116 IRQ_TYPE_LEVEL_HIGH>,
					<GIC_ESPI 117 IRQ_TYPE_LEVEL_HIGH>,
					<GIC_ESPI 118 IRQ_TYPE_LEVEL_HIGH>,
					<GIC_ESPI 119 IRQ_TYPE_LEVEL_HIGH>,
					<GIC_ESPI 120 IRQ_TYPE_LEVEL_HIGH>,
					<GIC_ESPI 121 IRQ_TYPE_LEVEL_HIGH>,
					<GIC_ESPI 122 IRQ_TYPE_LEVEL_HIGH>,
					<GIC_ESPI 123 IRQ_TYPE_LEVEL_HIGH>,
					<GIC_ESPI 124 IRQ_TYPE_LEVEL_HIGH>,
					<GIC_ESPI 125 IRQ_TYPE_LEVEL_HIGH>,
					<GIC_ESPI 126 IRQ_TYPE_LEVEL_HIGH>,
					<GIC_ESPI 127 IRQ_TYPE_LEVEL_HIGH>;

		};

		apps_smmu_1: iommu@15c00000 {
			compatible = "qcom,nord-smmu-500", "qcom,smmu-500", "arm,mmu-500";
			reg = <0x0 0x15c00000 0x0 0x100000>;
			#iommu-cells = <2>;
			#global-interrupts = <1>;
			dma-coherent;
			interrupts =	<GIC_SPI 882 IRQ_TYPE_LEVEL_HIGH>,
					<GIC_ESPI 128 IRQ_TYPE_LEVEL_HIGH>,
					<GIC_ESPI 129 IRQ_TYPE_LEVEL_HIGH>,
					<GIC_ESPI 130 IRQ_TYPE_LEVEL_HIGH>,
					<GIC_ESPI 131 IRQ_TYPE_LEVEL_HIGH>,
					<GIC_ESPI 132 IRQ_TYPE_LEVEL_HIGH>,
					<GIC_ESPI 133 IRQ_TYPE_LEVEL_HIGH>,
					<GIC_ESPI 134 IRQ_TYPE_LEVEL_HIGH>,
					<GIC_ESPI 135 IRQ_TYPE_LEVEL_HIGH>,
					<GIC_ESPI 136 IRQ_TYPE_LEVEL_HIGH>,
					<GIC_ESPI 137 IRQ_TYPE_LEVEL_HIGH>,
					<GIC_ESPI 138 IRQ_TYPE_LEVEL_HIGH>,
					<GIC_ESPI 139 IRQ_TYPE_LEVEL_HIGH>,
					<GIC_ESPI 140 IRQ_TYPE_LEVEL_HIGH>,
					<GIC_ESPI 141 IRQ_TYPE_LEVEL_HIGH>,
					<GIC_ESPI 142 IRQ_TYPE_LEVEL_HIGH>,
					<GIC_ESPI 143 IRQ_TYPE_LEVEL_HIGH>,
					<GIC_ESPI 144 IRQ_TYPE_LEVEL_HIGH>,
					<GIC_ESPI 145 IRQ_TYPE_LEVEL_HIGH>,
					<GIC_ESPI 146 IRQ_TYPE_LEVEL_HIGH>,
					<GIC_ESPI 147 IRQ_TYPE_LEVEL_HIGH>,
					<GIC_ESPI 148 IRQ_TYPE_LEVEL_HIGH>,
					<GIC_ESPI 149 IRQ_TYPE_LEVEL_HIGH>,
					<GIC_ESPI 150 IRQ_TYPE_LEVEL_HIGH>,
					<GIC_ESPI 151 IRQ_TYPE_LEVEL_HIGH>,
					<GIC_ESPI 152 IRQ_TYPE_LEVEL_HIGH>,
					<GIC_ESPI 153 IRQ_TYPE_LEVEL_HIGH>,
					<GIC_ESPI 154 IRQ_TYPE_LEVEL_HIGH>,
					<GIC_ESPI 155 IRQ_TYPE_LEVEL_HIGH>,
					<GIC_ESPI 156 IRQ_TYPE_LEVEL_HIGH>,
					<GIC_ESPI 157 IRQ_TYPE_LEVEL_HIGH>,
					<GIC_ESPI 158 IRQ_TYPE_LEVEL_HIGH>,
					<GIC_ESPI 159 IRQ_TYPE_LEVEL_HIGH>,
					<GIC_ESPI 160 IRQ_TYPE_LEVEL_HIGH>,
					<GIC_ESPI 161 IRQ_TYPE_LEVEL_HIGH>,
					<GIC_ESPI 162 IRQ_TYPE_LEVEL_HIGH>,
					<GIC_ESPI 163 IRQ_TYPE_LEVEL_HIGH>,
					<GIC_ESPI 164 IRQ_TYPE_LEVEL_HIGH>,
					<GIC_ESPI 165 IRQ_TYPE_LEVEL_HIGH>,
					<GIC_ESPI 166 IRQ_TYPE_LEVEL_HIGH>,
					<GIC_ESPI 167 IRQ_TYPE_LEVEL_HIGH>,
					<GIC_ESPI 168 IRQ_TYPE_LEVEL_HIGH>,
					<GIC_ESPI 169 IRQ_TYPE_LEVEL_HIGH>,
					<GIC_ESPI 170 IRQ_TYPE_LEVEL_HIGH>,
					<GIC_ESPI 171 IRQ_TYPE_LEVEL_HIGH>,
					<GIC_ESPI 172 IRQ_TYPE_LEVEL_HIGH>,
					<GIC_ESPI 173 IRQ_TYPE_LEVEL_HIGH>,
					<GIC_ESPI 174 IRQ_TYPE_LEVEL_HIGH>,
					<GIC_ESPI 175 IRQ_TYPE_LEVEL_HIGH>,
					<GIC_ESPI 176 IRQ_TYPE_LEVEL_HIGH>,
					<GIC_ESPI 177 IRQ_TYPE_LEVEL_HIGH>,
					<GIC_ESPI 178 IRQ_TYPE_LEVEL_HIGH>,
					<GIC_ESPI 179 IRQ_TYPE_LEVEL_HIGH>,
					<GIC_ESPI 180 IRQ_TYPE_LEVEL_HIGH>,
					<GIC_ESPI 181 IRQ_TYPE_LEVEL_HIGH>,
					<GIC_ESPI 182 IRQ_TYPE_LEVEL_HIGH>,
					<GIC_ESPI 183 IRQ_TYPE_LEVEL_HIGH>,
					<GIC_ESPI 184 IRQ_TYPE_LEVEL_HIGH>,
					<GIC_ESPI 185 IRQ_TYPE_LEVEL_HIGH>,
					<GIC_ESPI 186 IRQ_TYPE_LEVEL_HIGH>,
					<GIC_ESPI 187 IRQ_TYPE_LEVEL_HIGH>,
					<GIC_ESPI 188 IRQ_TYPE_LEVEL_HIGH>,
					<GIC_ESPI 189 IRQ_TYPE_LEVEL_HIGH>,
					<GIC_ESPI 190 IRQ_TYPE_LEVEL_HIGH>,
					<GIC_ESPI 191 IRQ_TYPE_LEVEL_HIGH>,
					<GIC_ESPI 192 IRQ_TYPE_LEVEL_HIGH>,
					<GIC_ESPI 193 IRQ_TYPE_LEVEL_HIGH>,
					<GIC_ESPI 194 IRQ_TYPE_LEVEL_HIGH>,
					<GIC_ESPI 195 IRQ_TYPE_LEVEL_HIGH>,
					<GIC_ESPI 196 IRQ_TYPE_LEVEL_HIGH>,
					<GIC_ESPI 197 IRQ_TYPE_LEVEL_HIGH>,
					<GIC_ESPI 198 IRQ_TYPE_LEVEL_HIGH>,
					<GIC_ESPI 199 IRQ_TYPE_LEVEL_HIGH>,
					<GIC_ESPI 200 IRQ_TYPE_LEVEL_HIGH>,
					<GIC_ESPI 201 IRQ_TYPE_LEVEL_HIGH>,
					<GIC_ESPI 202 IRQ_TYPE_LEVEL_HIGH>,
					<GIC_ESPI 203 IRQ_TYPE_LEVEL_HIGH>,
					<GIC_ESPI 204 IRQ_TYPE_LEVEL_HIGH>,
					<GIC_ESPI 205 IRQ_TYPE_LEVEL_HIGH>,
					<GIC_ESPI 206 IRQ_TYPE_LEVEL_HIGH>,
					<GIC_ESPI 207 IRQ_TYPE_LEVEL_HIGH>,
					<GIC_ESPI 208 IRQ_TYPE_LEVEL_HIGH>,
					<GIC_ESPI 209 IRQ_TYPE_LEVEL_HIGH>,
					<GIC_ESPI 210 IRQ_TYPE_LEVEL_HIGH>,
					<GIC_ESPI 211 IRQ_TYPE_LEVEL_HIGH>,
					<GIC_ESPI 212 IRQ_TYPE_LEVEL_HIGH>,
					<GIC_ESPI 213 IRQ_TYPE_LEVEL_HIGH>,
					<GIC_ESPI 214 IRQ_TYPE_LEVEL_HIGH>,
					<GIC_ESPI 215 IRQ_TYPE_LEVEL_HIGH>,
					<GIC_ESPI 216 IRQ_TYPE_LEVEL_HIGH>,
					<GIC_ESPI 217 IRQ_TYPE_LEVEL_HIGH>,
					<GIC_ESPI 218 IRQ_TYPE_LEVEL_HIGH>,
					<GIC_ESPI 219 IRQ_TYPE_LEVEL_HIGH>,
					<GIC_ESPI 220 IRQ_TYPE_LEVEL_HIGH>,
					<GIC_ESPI 221 IRQ_TYPE_LEVEL_HIGH>,
					<GIC_ESPI 222 IRQ_TYPE_LEVEL_HIGH>,
					<GIC_ESPI 223 IRQ_TYPE_LEVEL_HIGH>;
		};

		apps_smmu_2: iommu@15e00000 {
			compatible = "qcom,nord-smmu-500", "qcom,smmu-500", "arm,mmu-500";
			reg = <0x0 0x15e00000 0x0 0x100000>;
			#iommu-cells = <2>;
			#global-interrupts = <1>;
			dma-coherent;
			interrupts =	<GIC_SPI 877 IRQ_TYPE_LEVEL_HIGH>,
					<GIC_ESPI 224 IRQ_TYPE_LEVEL_HIGH>,
					<GIC_ESPI 225 IRQ_TYPE_LEVEL_HIGH>,
					<GIC_ESPI 226 IRQ_TYPE_LEVEL_HIGH>,
					<GIC_ESPI 227 IRQ_TYPE_LEVEL_HIGH>,
					<GIC_ESPI 228 IRQ_TYPE_LEVEL_HIGH>,
					<GIC_ESPI 229 IRQ_TYPE_LEVEL_HIGH>,
					<GIC_ESPI 230 IRQ_TYPE_LEVEL_HIGH>,
					<GIC_ESPI 231 IRQ_TYPE_LEVEL_HIGH>,
					<GIC_ESPI 232 IRQ_TYPE_LEVEL_HIGH>,
					<GIC_ESPI 233 IRQ_TYPE_LEVEL_HIGH>,
					<GIC_ESPI 234 IRQ_TYPE_LEVEL_HIGH>,
					<GIC_ESPI 235 IRQ_TYPE_LEVEL_HIGH>,
					<GIC_ESPI 236 IRQ_TYPE_LEVEL_HIGH>,
					<GIC_ESPI 237 IRQ_TYPE_LEVEL_HIGH>,
					<GIC_ESPI 238 IRQ_TYPE_LEVEL_HIGH>,
					<GIC_ESPI 239 IRQ_TYPE_LEVEL_HIGH>,
					<GIC_ESPI 240 IRQ_TYPE_LEVEL_HIGH>,
					<GIC_ESPI 241 IRQ_TYPE_LEVEL_HIGH>,
					<GIC_ESPI 242 IRQ_TYPE_LEVEL_HIGH>,
					<GIC_ESPI 243 IRQ_TYPE_LEVEL_HIGH>,
					<GIC_ESPI 244 IRQ_TYPE_LEVEL_HIGH>,
					<GIC_ESPI 245 IRQ_TYPE_LEVEL_HIGH>,
					<GIC_ESPI 246 IRQ_TYPE_LEVEL_HIGH>,
					<GIC_ESPI 247 IRQ_TYPE_LEVEL_HIGH>,
					<GIC_ESPI 248 IRQ_TYPE_LEVEL_HIGH>,
					<GIC_ESPI 249 IRQ_TYPE_LEVEL_HIGH>,
					<GIC_ESPI 250 IRQ_TYPE_LEVEL_HIGH>,
					<GIC_ESPI 251 IRQ_TYPE_LEVEL_HIGH>,
					<GIC_ESPI 252 IRQ_TYPE_LEVEL_HIGH>,
					<GIC_ESPI 253 IRQ_TYPE_LEVEL_HIGH>,
					<GIC_ESPI 254 IRQ_TYPE_LEVEL_HIGH>,
					<GIC_ESPI 255 IRQ_TYPE_LEVEL_HIGH>,
					<GIC_ESPI 256 IRQ_TYPE_LEVEL_HIGH>,
					<GIC_ESPI 257 IRQ_TYPE_LEVEL_HIGH>,
					<GIC_ESPI 258 IRQ_TYPE_LEVEL_HIGH>,
					<GIC_ESPI 259 IRQ_TYPE_LEVEL_HIGH>,
					<GIC_ESPI 260 IRQ_TYPE_LEVEL_HIGH>,
					<GIC_ESPI 261 IRQ_TYPE_LEVEL_HIGH>,
					<GIC_ESPI 262 IRQ_TYPE_LEVEL_HIGH>,
					<GIC_ESPI 263 IRQ_TYPE_LEVEL_HIGH>,
					<GIC_ESPI 264 IRQ_TYPE_LEVEL_HIGH>,
					<GIC_ESPI 265 IRQ_TYPE_LEVEL_HIGH>,
					<GIC_ESPI 266 IRQ_TYPE_LEVEL_HIGH>,
					<GIC_ESPI 267 IRQ_TYPE_LEVEL_HIGH>,
					<GIC_ESPI 268 IRQ_TYPE_LEVEL_HIGH>,
					<GIC_ESPI 269 IRQ_TYPE_LEVEL_HIGH>,
					<GIC_ESPI 270 IRQ_TYPE_LEVEL_HIGH>,
					<GIC_ESPI 271 IRQ_TYPE_LEVEL_HIGH>,
					<GIC_ESPI 272 IRQ_TYPE_LEVEL_HIGH>,
					<GIC_ESPI 273 IRQ_TYPE_LEVEL_HIGH>,
					<GIC_ESPI 274 IRQ_TYPE_LEVEL_HIGH>,
					<GIC_ESPI 275 IRQ_TYPE_LEVEL_HIGH>,
					<GIC_ESPI 276 IRQ_TYPE_LEVEL_HIGH>,
					<GIC_ESPI 277 IRQ_TYPE_LEVEL_HIGH>,
					<GIC_ESPI 278 IRQ_TYPE_LEVEL_HIGH>,
					<GIC_ESPI 279 IRQ_TYPE_LEVEL_HIGH>,
					<GIC_ESPI 280 IRQ_TYPE_LEVEL_HIGH>,
					<GIC_ESPI 281 IRQ_TYPE_LEVEL_HIGH>,
					<GIC_ESPI 282 IRQ_TYPE_LEVEL_HIGH>,
					<GIC_ESPI 283 IRQ_TYPE_LEVEL_HIGH>,
					<GIC_ESPI 284 IRQ_TYPE_LEVEL_HIGH>,
					<GIC_ESPI 285 IRQ_TYPE_LEVEL_HIGH>,
					<GIC_ESPI 286 IRQ_TYPE_LEVEL_HIGH>,
					<GIC_ESPI 287 IRQ_TYPE_LEVEL_HIGH>,
					<GIC_ESPI 288 IRQ_TYPE_LEVEL_HIGH>,
					<GIC_ESPI 289 IRQ_TYPE_LEVEL_HIGH>,
					<GIC_ESPI 290 IRQ_TYPE_LEVEL_HIGH>,
					<GIC_ESPI 291 IRQ_TYPE_LEVEL_HIGH>,
					<GIC_ESPI 292 IRQ_TYPE_LEVEL_HIGH>,
					<GIC_ESPI 293 IRQ_TYPE_LEVEL_HIGH>,
					<GIC_ESPI 294 IRQ_TYPE_LEVEL_HIGH>,
					<GIC_ESPI 295 IRQ_TYPE_LEVEL_HIGH>,
					<GIC_ESPI 296 IRQ_TYPE_LEVEL_HIGH>,
					<GIC_ESPI 297 IRQ_TYPE_LEVEL_HIGH>,
					<GIC_ESPI 298 IRQ_TYPE_LEVEL_HIGH>,
					<GIC_ESPI 299 IRQ_TYPE_LEVEL_HIGH>,
					<GIC_ESPI 300 IRQ_TYPE_LEVEL_HIGH>,
					<GIC_ESPI 301 IRQ_TYPE_LEVEL_HIGH>,
					<GIC_ESPI 302 IRQ_TYPE_LEVEL_HIGH>,
					<GIC_ESPI 303 IRQ_TYPE_LEVEL_HIGH>,
					<GIC_ESPI 304 IRQ_TYPE_LEVEL_HIGH>,
					<GIC_ESPI 305 IRQ_TYPE_LEVEL_HIGH>,
					<GIC_ESPI 306 IRQ_TYPE_LEVEL_HIGH>,
					<GIC_ESPI 307 IRQ_TYPE_LEVEL_HIGH>,
					<GIC_ESPI 308 IRQ_TYPE_LEVEL_HIGH>,
					<GIC_ESPI 309 IRQ_TYPE_LEVEL_HIGH>,
					<GIC_ESPI 310 IRQ_TYPE_LEVEL_HIGH>,
					<GIC_ESPI 311 IRQ_TYPE_LEVEL_HIGH>,
					<GIC_ESPI 312 IRQ_TYPE_LEVEL_HIGH>,
					<GIC_ESPI 313 IRQ_TYPE_LEVEL_HIGH>,
					<GIC_ESPI 314 IRQ_TYPE_LEVEL_HIGH>,
					<GIC_ESPI 315 IRQ_TYPE_LEVEL_HIGH>,
					<GIC_ESPI 316 IRQ_TYPE_LEVEL_HIGH>,
					<GIC_ESPI 317 IRQ_TYPE_LEVEL_HIGH>,
					<GIC_ESPI 318 IRQ_TYPE_LEVEL_HIGH>,
					<GIC_ESPI 319 IRQ_TYPE_LEVEL_HIGH>;

		};

		pcie_smmu: iommu@9980000 {
			compatible = "arm,smmu-v3";
			reg = <0x0 0x9980000 0x0 0x20000>;
			interrupts = <GIC_SPI 898 IRQ_TYPE_EDGE_RISING>,
				<GIC_SPI 900 IRQ_TYPE_EDGE_RISING>,
				<GIC_SPI 902 IRQ_TYPE_EDGE_RISING>;
			interrupt-names = "eventq", "cmdq-sync", "gerror";
			dma-coherent;
			#iommu-cells = <1>;
			status = "disabled";
		};

		rng: rng@10c3000 {
			compatible = "qcom,nord-trng", "qcom,trng";
			reg = <0x0 0x10c3000 0x0 0x1000>;
		};

		ufshc_mem: ufshc@1d44000 {
			compatible = "qcom,nord-auto-ufshc","qcom,sa8255p-ufshc";
			reg =	<0x0 0x1d44000 0x0 0x3000>;

			interrupts = <GIC_SPI 265 IRQ_TYPE_LEVEL_HIGH>;
			lanes-per-direction = <1>;

			msi-parent = <&gic_its 0x14c0>;

			iommus = <&apps_smmu_0 0x14c0 0x0>;
			dma-coherent;

			power-domains = <&scmi3_pd 0>;

		};

		adreno_smmu_0: iommu@3da0000 {
			compatible = "qcom,nord-smmu-500", "qcom,adreno-smmu",
				     "qcom,smmu-500", "arm,mmu-500";
			reg = <0x0 0x03da0000 0x0 0x40000>;
			#iommu-cells = <2>;
			#global-interrupts = <1>;
			dma-coherent;
			interrupts = <GIC_SPI 673 IRQ_TYPE_LEVEL_HIGH>,
				<GIC_SPI 678 IRQ_TYPE_LEVEL_HIGH>,
				<GIC_SPI 679 IRQ_TYPE_LEVEL_HIGH>,
				<GIC_SPI 680 IRQ_TYPE_LEVEL_HIGH>,
				<GIC_SPI 681 IRQ_TYPE_LEVEL_HIGH>,
				<GIC_SPI 682 IRQ_TYPE_LEVEL_HIGH>,
				<GIC_SPI 683 IRQ_TYPE_LEVEL_HIGH>,
				<GIC_SPI 684 IRQ_TYPE_LEVEL_HIGH>,
				<GIC_SPI 685 IRQ_TYPE_LEVEL_HIGH>,
				<GIC_SPI 686 IRQ_TYPE_LEVEL_HIGH>,
				<GIC_SPI 687 IRQ_TYPE_LEVEL_HIGH>,
				<GIC_SPI 688 IRQ_TYPE_LEVEL_HIGH>,
				<GIC_SPI 422 IRQ_TYPE_LEVEL_HIGH>,
				<GIC_SPI 476 IRQ_TYPE_LEVEL_HIGH>,
				<GIC_SPI 679 IRQ_TYPE_LEVEL_HIGH>,
				<GIC_SPI 574 IRQ_TYPE_LEVEL_HIGH>,
				<GIC_SPI 575 IRQ_TYPE_LEVEL_HIGH>,
				<GIC_SPI 576 IRQ_TYPE_LEVEL_HIGH>,
				<GIC_SPI 577 IRQ_TYPE_LEVEL_HIGH>,
				<GIC_SPI 660 IRQ_TYPE_LEVEL_HIGH>,
				<GIC_SPI 662 IRQ_TYPE_LEVEL_HIGH>,
				<GIC_SPI 665 IRQ_TYPE_LEVEL_HIGH>,
				<GIC_SPI 666 IRQ_TYPE_LEVEL_HIGH>,
				<GIC_SPI 667 IRQ_TYPE_LEVEL_HIGH>,
				<GIC_SPI 669 IRQ_TYPE_LEVEL_HIGH>,
				<GIC_SPI 670 IRQ_TYPE_LEVEL_HIGH>,
				<GIC_SPI 670 IRQ_TYPE_LEVEL_HIGH>;

			power-domains = <&scmi15_pd 0>;
		};

		pdp_mbox0: mailbox@19980000 {
			compatible = "qcom,nord-cpucp-mbox", "qcom,x1e80100-cpucp-mbox";
			reg = <0x0 0x19980000 0x0 0x300>,
				<0x0 0x17610000 0x0 0x4c08>;
			#mbox-cells = <1>;
			interrupts = <GIC_SPI 56 IRQ_TYPE_LEVEL_HIGH>;
		};

		cpucp_mbox: mailbox@18830000 {
			compatible = "qcom,nord-cpucp-mbox", "qcom,x1e80100-cpucp-mbox";
			reg =	<0x0 0x18830000 0x0 0x300>,
				<0x0 0x17620000 0x0 0x4c08>;
			#mbox-cells = <1>;
			interrupts = <GIC_SPI 50 IRQ_TYPE_LEVEL_HIGH>;
		};
	};

	timer {
			compatible = "arm,armv8-timer";
			interrupts = <GIC_PPI 13 (GIC_CPU_MASK_SIMPLE(8) | IRQ_TYPE_LEVEL_LOW)>,
				     <GIC_PPI 14 (GIC_CPU_MASK_SIMPLE(8) | IRQ_TYPE_LEVEL_LOW)>,
				     <GIC_PPI 11 (GIC_CPU_MASK_SIMPLE(8) | IRQ_TYPE_LEVEL_LOW)>,
				     <GIC_PPI 12 (GIC_CPU_MASK_SIMPLE(8) | IRQ_TYPE_LEVEL_LOW)>;
	};

	thermal_zones: thermal-zones {
		ddr-0-0-thermal {
			polling-delay-passive = <0>;
			polling-delay = <0>;

			thermal-sensors = <&tsens0 0>;

			trips {
				trip-point0 {
					temperature = <105000>;
					hysteresis = <10000>;
					type = "passive";
				};

				trip-point1 {
					temperature = <115000>;
					hysteresis = <10000>;
					type = "passive";
				};
			};
		};

		cpu-0-0-0-thermal {
			polling-delay-passive = <0>;
			polling-delay = <0>;

			thermal-sensors = <&tsens0 1>;

			trips {
				trip-point0 {
					temperature = <105000>;
					hysteresis = <10000>;
					type = "passive";
				};

				trip-point1 {
					temperature = <125000>;
					hysteresis = <10000>;
					type = "passive";
				};
			};
		};

		cpu-0-1-0-thermal {
			polling-delay-passive = <0>;
			polling-delay = <0>;

			thermal-sensors = <&tsens0 2>;

			trips {
				trip-point0 {
					temperature = <105000>;
					hysteresis = <10000>;
					type = "passive";
				};

				trip-point1 {
					temperature = <125000>;
					hysteresis = <10000>;
					type = "passive";
				};
			};
		};

		cpu-0-2-0-thermal {
			polling-delay-passive = <0>;
			polling-delay = <0>;

			thermal-sensors = <&tsens0 3>;

			trips {
				trip-point0 {
					temperature = <105000>;
					hysteresis = <10000>;
					type = "passive";
				};

				trip-point1 {
					temperature = <125000>;
					hysteresis = <10000>;
					type = "passive";
				};
			};
		};

		cpu-0-3-0-thermal {
			polling-delay-passive = <0>;
			polling-delay = <0>;

			thermal-sensors = <&tsens0 4>;

			trips {
				trip-point0 {
					temperature = <105000>;
					hysteresis = <10000>;
					type = "passive";
				};

				trip-point1 {
					temperature = <125000>;
					hysteresis = <10000>;
					type = "passive";
				};
			};
		};

		cpu-0-4-0-thermal {
			polling-delay-passive = <0>;
			polling-delay = <0>;

			thermal-sensors = <&tsens0 5>;

			trips {
				trip-point0 {
					temperature = <105000>;
					hysteresis = <10000>;
					type = "passive";
				};

				trip-point1 {
					temperature = <125000>;
					hysteresis = <10000>;
					type = "passive";
				};
			};
		};

		cpu-0-5-0-thermal {
			polling-delay-passive = <0>;
			polling-delay = <0>;

			thermal-sensors = <&tsens0 6>;

			trips {
				trip-point0 {
					temperature = <105000>;
					hysteresis = <10000>;
					type = "passive";
				};

				trip-point1 {
					temperature = <125000>;
					hysteresis = <10000>;
					type = "passive";
				};
			};
		};

		cpullc-0-0-thermal {
			polling-delay-passive = <0>;
			polling-delay = <0>;

			thermal-sensors = <&tsens0 7>;

			trips {
				trip-point0 {
					temperature = <105000>;
					hysteresis = <10000>;
					type = "passive";
				};

				trip-point1 {
					temperature = <115000>;
					hysteresis = <10000>;
					type = "passive";
				};
			};
		};

		cpu-1-0-0-thermal {
			polling-delay-passive = <0>;
			polling-delay = <0>;

			thermal-sensors = <&tsens0 8>;

			trips {
				trip-point0 {
					temperature = <105000>;
					hysteresis = <10000>;
					type = "passive";
				};

				trip-point1 {
					temperature = <125000>;
					hysteresis = <10000>;
					type = "passive";
				};
			};
		};

		cpu-1-1-0-thermal {
			polling-delay-passive = <0>;
			polling-delay = <0>;

			thermal-sensors = <&tsens0 9>;

			trips {
				trip-point0 {
					temperature = <105000>;
					hysteresis = <10000>;
					type = "passive";
				};

				trip-point1 {
					temperature = <125000>;
					hysteresis = <10000>;
					type = "passive";
				};
			};
		};

		cpu-1-2-0-thermal {
			polling-delay-passive = <0>;
			polling-delay = <0>;

			thermal-sensors = <&tsens0 10>;

			trips {
				trip-point0 {
					temperature = <105000>;
					hysteresis = <10000>;
					type = "passive";
				};

				trip-point1 {
					temperature = <125000>;
					hysteresis = <10000>;
					type = "passive";
				};
			};
		};

		cpu-1-3-0-thermal {
			polling-delay-passive = <0>;
			polling-delay = <0>;

			thermal-sensors = <&tsens0 11>;

			trips {
				trip-point0 {
					temperature = <105000>;
					hysteresis = <10000>;
					type = "passive";
				};

				trip-point1 {
					temperature = <125000>;
					hysteresis = <10000>;
					type = "passive";
				};
			};
		};

		cpu-1-4-0-thermal {
			polling-delay-passive = <0>;
			polling-delay = <0>;

			thermal-sensors = <&tsens0 12>;

			trips {
				trip-point0 {
					temperature = <105000>;
					hysteresis = <10000>;
					type = "passive";
				};

				trip-point1 {
					temperature = <125000>;
					hysteresis = <10000>;
					type = "passive";
				};
			};
		};

		cpu-1-5-0-thermal {
			polling-delay-passive = <0>;
			polling-delay = <0>;

			thermal-sensors = <&tsens0 13>;

			trips {
				trip-point0 {
					temperature = <105000>;
					hysteresis = <10000>;
					type = "passive";
				};

				trip-point1 {
					temperature = <125000>;
					hysteresis = <10000>;
					type = "passive";
				};
			};
		};

		cpullc-1-0-thermal {
			polling-delay-passive = <0>;
			polling-delay = <0>;

			thermal-sensors = <&tsens0 14>;

			trips {
				trip-point0 {
					temperature = <105000>;
					hysteresis = <10000>;
					type = "passive";
				};

				trip-point1 {
					temperature = <115000>;
					hysteresis = <10000>;
					type = "passive";
				};
			};
		};

		ddr-1-0-thermal {
			polling-delay-passive = <0>;
			polling-delay = <0>;

			thermal-sensors = <&tsens0 15>;

			trips {
				trip-point0 {
					temperature = <105000>;
					hysteresis = <10000>;
					type = "passive";
				};

				trip-point1 {
					temperature = <115000>;
					hysteresis = <10000>;
					type = "passive";
				};
			};
		};

		ddr-0-1-thermal {
			polling-delay-passive = <0>;
			polling-delay = <0>;

			thermal-sensors = <&tsens1 0>;

			trips {
				trip-point0 {
					temperature = <105000>;
					hysteresis = <10000>;
					type = "passive";
				};

				trip-point1 {
					temperature = <115000>;
					hysteresis = <10000>;
					type = "passive";
				};
			};
		};

		cpu-0-0-1-thermal {
			polling-delay-passive = <0>;
			polling-delay = <0>;

			thermal-sensors = <&tsens1 1>;

			trips {
				trip-point0 {
					temperature = <105000>;
					hysteresis = <10000>;
					type = "passive";
				};

				trip-point1 {
					temperature = <125000>;
					hysteresis = <10000>;
					type = "passive";
				};
			};
		};

		cpu-0-1-1-thermal {
			polling-delay-passive = <0>;
			polling-delay = <0>;

			thermal-sensors = <&tsens1 2>;

			trips {
				trip-point0 {
					temperature = <105000>;
					hysteresis = <10000>;
					type = "passive";
				};

				trip-point1 {
					temperature = <125000>;
					hysteresis = <10000>;
					type = "passive";
				};
			};
		};

		cpu-0-2-1-thermal {
			polling-delay-passive = <0>;
			polling-delay = <0>;

			thermal-sensors = <&tsens1 3>;

			trips {
				trip-point0 {
					temperature = <105000>;
					hysteresis = <10000>;
					type = "passive";
				};

				trip-point1 {
					temperature = <125000>;
					hysteresis = <10000>;
					type = "passive";
				};
			};
		};

		cpu-0-3-1-thermal {
			polling-delay-passive = <0>;
			polling-delay = <0>;

			thermal-sensors = <&tsens1 4>;

			trips {
				trip-point0 {
					temperature = <105000>;
					hysteresis = <10000>;
					type = "passive";
				};

				trip-point1 {
					temperature = <125000>;
					hysteresis = <10000>;
					type = "passive";
				};
			};
		};

		cpu-0-4-1-thermal {
			polling-delay-passive = <0>;
			polling-delay = <0>;

			thermal-sensors = <&tsens1 5>;

			trips {
				trip-point0 {
					temperature = <105000>;
					hysteresis = <10000>;
					type = "passive";
				};

				trip-point1 {
					temperature = <125000>;
					hysteresis = <10000>;
					type = "passive";
				};
			};
		};

		cpu-0-5-1-thermal {
			polling-delay-passive = <0>;
			polling-delay = <0>;

			thermal-sensors = <&tsens1 6>;

			trips {
				trip-point0 {
					temperature = <105000>;
					hysteresis = <10000>;
					type = "passive";
				};

				trip-point1 {
					temperature = <125000>;
					hysteresis = <10000>;
					type = "passive";
				};
			};
		};

		cpullc-0-1-thermal {
			polling-delay-passive = <0>;
			polling-delay = <0>;

			thermal-sensors = <&tsens1 7>;

			trips {
				trip-point0 {
					temperature = <105000>;
					hysteresis = <10000>;
					type = "passive";
				};

				trip-point1 {
					temperature = <115000>;
					hysteresis = <10000>;
					type = "passive";
				};
			};
		};

		cpu-1-0-1-thermal {
			polling-delay-passive = <0>;
			polling-delay = <0>;

			thermal-sensors = <&tsens1 8>;

			trips {
				trip-point0 {
					temperature = <105000>;
					hysteresis = <10000>;
					type = "passive";
				};

				trip-point1 {
					temperature = <125000>;
					hysteresis = <10000>;
					type = "passive";
				};
			};
		};

		cpu-1-1-1-thermal {
			polling-delay-passive = <0>;
			polling-delay = <0>;

			thermal-sensors = <&tsens1 9>;

			trips {
				trip-point0 {
					temperature = <105000>;
					hysteresis = <10000>;
					type = "passive";
				};

				trip-point1 {
					temperature = <125000>;
					hysteresis = <10000>;
					type = "passive";
				};
			};
		};

		cpu-1-2-1-thermal {
			polling-delay-passive = <0>;
			polling-delay = <0>;

			thermal-sensors = <&tsens1 10>;

			trips {
				trip-point0 {
					temperature = <105000>;
					hysteresis = <10000>;
					type = "passive";
				};

				trip-point1 {
					temperature = <125000>;
					hysteresis = <10000>;
					type = "passive";
				};
			};
		};

		cpu-1-3-1-thermal {
			polling-delay-passive = <0>;
			polling-delay = <0>;

			thermal-sensors = <&tsens1 11>;

			trips {
				trip-point0 {
					temperature = <105000>;
					hysteresis = <10000>;
					type = "passive";
				};

				trip-point1 {
					temperature = <125000>;
					hysteresis = <10000>;
					type = "passive";
				};
			};
		};

		cpu-1-4-1-thermal {
			polling-delay-passive = <0>;
			polling-delay = <0>;

			thermal-sensors = <&tsens1 12>;

			trips {
				trip-point0 {
					temperature = <105000>;
					hysteresis = <10000>;
					type = "passive";
				};

				trip-point1 {
					temperature = <125000>;
					hysteresis = <10000>;
					type = "passive";
				};
			};
		};

		cpu-1-5-1-thermal {
			polling-delay-passive = <0>;
			polling-delay = <0>;

			thermal-sensors = <&tsens1 13>;

			trips {
				trip-point0 {
					temperature = <105000>;
					hysteresis = <10000>;
					type = "passive";
				};

				trip-point1 {
					temperature = <125000>;
					hysteresis = <10000>;
					type = "passive";
				};
			};
		};

		cpullc-1-1-thermal {
			polling-delay-passive = <0>;
			polling-delay = <0>;

			thermal-sensors = <&tsens1 14>;

			trips {
				trip-point0 {
					temperature = <105000>;
					hysteresis = <10000>;
					type = "passive";
				};

				trip-point1 {
					temperature = <115000>;
					hysteresis = <10000>;
					type = "passive";
				};
			};
		};

		ddr-1-1-thermal {
			polling-delay-passive = <0>;
			polling-delay = <0>;

			thermal-sensors = <&tsens1 15>;

			trips {
				trip-point0 {
					temperature = <105000>;
					hysteresis = <10000>;
					type = "passive";
				};

				trip-point1 {
					temperature = <115000>;
					hysteresis = <10000>;
					type = "passive";
				};
			};
		};

		amux-2-thermal {
			polling-delay-passive = <0>;
			polling-delay = <0>;

			thermal-sensors = <&tsens2 0>;

			trips {
				trip-point0 {
					temperature = <105000>;
					hysteresis = <10000>;
					type = "passive";
				};

				trip-point1 {
					temperature = <115000>;
					hysteresis = <10000>;
					type = "passive";
				};
			};
		};

		cpu-2-0-0-thermal {
			polling-delay-passive = <0>;
			polling-delay = <0>;

			thermal-sensors = <&tsens2 1>;

			trips {
				trip-point0 {
					temperature = <105000>;
					hysteresis = <10000>;
					type = "passive";
				};

				trip-point1 {
					temperature = <125000>;
					hysteresis = <10000>;
					type = "passive";
				};
			};
		};

		cpu-2-1-0-thermal {
			polling-delay-passive = <0>;
			polling-delay = <0>;

			thermal-sensors = <&tsens2 2>;

			trips {
				trip-point0 {
					temperature = <105000>;
					hysteresis = <10000>;
					type = "passive";
				};

				trip-point1 {
					temperature = <125000>;
					hysteresis = <10000>;
					type = "passive";
				};
			};
		};

		cpu-2-2-0-thermal {
			polling-delay-passive = <0>;
			polling-delay = <0>;

			thermal-sensors = <&tsens2 3>;

			trips {
				trip-point0 {
					temperature = <105000>;
					hysteresis = <10000>;
					type = "passive";
				};

				trip-point1 {
					temperature = <125000>;
					hysteresis = <10000>;
					type = "passive";
				};
			};
		};

		cpu-2-3-0-thermal {
			polling-delay-passive = <0>;
			polling-delay = <0>;

			thermal-sensors = <&tsens2 4>;

			trips {
				trip-point0 {
					temperature = <105000>;
					hysteresis = <10000>;
					type = "passive";
				};

				trip-point1 {
					temperature = <125000>;
					hysteresis = <10000>;
					type = "passive";
				};
			};
		};

		cpu-2-4-0-thermal {
			polling-delay-passive = <0>;
			polling-delay = <0>;

			thermal-sensors = <&tsens2 5>;

			trips {
				trip-point0 {
					temperature = <105000>;
					hysteresis = <10000>;
					type = "passive";
				};

				trip-point1 {
					temperature = <125000>;
					hysteresis = <10000>;
					type = "passive";
				};
			};
		};

		cpu-2-5-0-thermal {
			polling-delay-passive = <0>;
			polling-delay = <0>;

			thermal-sensors = <&tsens2 6>;

			trips {
				trip-point0 {
					temperature = <105000>;
					hysteresis = <10000>;
					type = "passive";
				};

				trip-point1 {
					temperature = <125000>;
					hysteresis = <10000>;
					type = "passive";
				};
			};
		};

		cpullc-2-0-thermal {
			polling-delay-passive = <0>;
			polling-delay = <0>;

			thermal-sensors = <&tsens2 7>;

			trips {
				trip-point0 {
					temperature = <105000>;
					hysteresis = <10000>;
					type = "passive";
				};

				trip-point1 {
					temperature = <115000>;
					hysteresis = <10000>;
					type = "passive";
				};
			};
		};

		audhvx-0-0-thermal {
			polling-delay-passive = <0>;
			polling-delay = <0>;

			thermal-sensors = <&tsens2 8>;

			trips {
				trip-point0 {
					temperature = <105000>;
					hysteresis = <10000>;
					type = "passive";
				};

				trip-point1 {
					temperature = <115000>;
					hysteresis = <10000>;
					type = "passive";
				};
			};
		};

		audhmx-0-0-thermal {
			polling-delay-passive = <0>;
			polling-delay = <0>;

			thermal-sensors = <&tsens2 9>;

			trips {
				trip-point0 {
					temperature = <105000>;
					hysteresis = <10000>;
					type = "passive";
				};

				trip-point1 {
					temperature = <115000>;
					hysteresis = <10000>;
					type = "passive";
				};
			};
		};

		audhvx-1-0-thermal {
			polling-delay-passive = <0>;
			polling-delay = <0>;

			thermal-sensors = <&tsens2 10>;

			trips {
				trip-point0 {
					temperature = <105000>;
					hysteresis = <10000>;
					type = "passive";
				};

				trip-point1 {
					temperature = <115000>;
					hysteresis = <10000>;
					type = "passive";
				};
			};
		};

		audhmx-1-0-thermal {
			polling-delay-passive = <0>;
			polling-delay = <0>;

			thermal-sensors = <&tsens2 11>;

			trips {
				trip-point0 {
					temperature = <105000>;
					hysteresis = <10000>;
					type = "passive";
				};

				trip-point1 {
					temperature = <115000>;
					hysteresis = <10000>;
					type = "passive";
				};
			};
		};

		audhvx-2-0-thermal {
			polling-delay-passive = <0>;
			polling-delay = <0>;

			thermal-sensors = <&tsens2 12>;

			trips {
				trip-point0 {
					temperature = <105000>;
					hysteresis = <10000>;
					type = "passive";
				};

				trip-point1 {
					temperature = <115000>;
					hysteresis = <10000>;
					type = "passive";
				};
			};
		};

		audhmx-2-0-thermal {
			polling-delay-passive = <0>;
			polling-delay = <0>;

			thermal-sensors = <&tsens2 13>;

			trips {
				trip-point0 {
					temperature = <105000>;
					hysteresis = <10000>;
					type = "passive";
				};

				trip-point1 {
					temperature = <115000>;
					hysteresis = <10000>;
					type = "passive";
				};
			};
		};

		pcie-0-thermal {
			polling-delay-passive = <0>;
			polling-delay = <0>;

			thermal-sensors = <&tsens2 15>;

			trips {
				trip-point0 {
					temperature = <105000>;
					hysteresis = <10000>;
					type = "passive";
				};

				trip-point1 {
					temperature = <115000>;
					hysteresis = <10000>;
					type = "passive";
				};
			};
		};

		amux-3-thermal {
			polling-delay-passive = <0>;
			polling-delay = <0>;

			thermal-sensors = <&tsens3 0>;

			trips {
				trip-point0 {
					temperature = <105000>;
					hysteresis = <10000>;
					type = "passive";
				};

				trip-point1 {
					temperature = <115000>;
					hysteresis = <10000>;
					type = "passive";
				};
			};
		};

		cpu-2-0-1-thermal {
			polling-delay-passive = <0>;
			polling-delay = <0>;

			thermal-sensors = <&tsens3 1>;

			trips {
				trip-point0 {
					temperature = <105000>;
					hysteresis = <10000>;
					type = "passive";
				};

				trip-point1 {
					temperature = <125000>;
					hysteresis = <10000>;
					type = "passive";
				};
			};
		};

		cpu-2-1-1-thermal {
			polling-delay-passive = <0>;
			polling-delay = <0>;

			thermal-sensors = <&tsens3 2>;

			trips {
				trip-point0 {
					temperature = <105000>;
					hysteresis = <10000>;
					type = "passive";
				};

				trip-point1 {
					temperature = <125000>;
					hysteresis = <10000>;
					type = "passive";
				};
			};
		};

		cpu-2-2-1-thermal {
			polling-delay-passive = <0>;
			polling-delay = <0>;

			thermal-sensors = <&tsens3 3>;

			trips {
				trip-point0 {
					temperature = <105000>;
					hysteresis = <10000>;
					type = "passive";
				};

				trip-point1 {
					temperature = <125000>;
					hysteresis = <10000>;
					type = "passive";
				};
			};
		};

		cpu-2-3-1-thermal {
			polling-delay-passive = <0>;
			polling-delay = <0>;

			thermal-sensors = <&tsens3 4>;

			trips {
				trip-point0 {
					temperature = <105000>;
					hysteresis = <10000>;
					type = "passive";
				};

				trip-point1 {
					temperature = <125000>;
					hysteresis = <10000>;
					type = "passive";
				};
			};
		};

		cpu-2-4-1-thermal {
			polling-delay-passive = <0>;
			polling-delay = <0>;

			thermal-sensors = <&tsens3 5>;

			trips {
				trip-point0 {
					temperature = <105000>;
					hysteresis = <10000>;
					type = "passive";
				};

				trip-point1 {
					temperature = <125000>;
					hysteresis = <10000>;
					type = "passive";
				};
			};
		};

		cpu-2-5-1-thermal {
			polling-delay-passive = <0>;
			polling-delay = <0>;

			thermal-sensors = <&tsens3 6>;

			trips {
				trip-point0 {
					temperature = <105000>;
					hysteresis = <10000>;
					type = "passive";
				};

				trip-point1 {
					temperature = <125000>;
					hysteresis = <10000>;
					type = "passive";
				};
			};
		};

		cpullc-2-1-thermal {
			polling-delay-passive = <0>;
			polling-delay = <0>;

			thermal-sensors = <&tsens3 7>;

			trips {
				trip-point0 {
					temperature = <105000>;
					hysteresis = <10000>;
					type = "passive";
				};

				trip-point1 {
					temperature = <115000>;
					hysteresis = <10000>;
					type = "passive";
				};
			};
		};

		audhvx-0-1-thermal {
			polling-delay-passive = <0>;
			polling-delay = <0>;

			thermal-sensors = <&tsens3 8>;

			trips {
				trip-point0 {
					temperature = <105000>;
					hysteresis = <10000>;
					type = "passive";
				};

				trip-point1 {
					temperature = <115000>;
					hysteresis = <10000>;
					type = "passive";
				};
			};
		};

		audhmx-0-1-thermal {
			polling-delay-passive = <0>;
			polling-delay = <0>;

			thermal-sensors = <&tsens3 9>;

			trips {
				trip-point0 {
					temperature = <105000>;
					hysteresis = <10000>;
					type = "passive";
				};

				trip-point1 {
					temperature = <115000>;
					hysteresis = <10000>;
					type = "passive";
				};
			};
		};

		audhvx-1-1-thermal {
			polling-delay-passive = <0>;
			polling-delay = <0>;

			thermal-sensors = <&tsens3 10>;

			trips {
				trip-point0 {
					temperature = <105000>;
					hysteresis = <10000>;
					type = "passive";
				};

				trip-point1 {
					temperature = <115000>;
					hysteresis = <10000>;
					type = "passive";
				};
			};
		};

		audhmx-1-1-thermal {
			polling-delay-passive = <0>;
			polling-delay = <0>;

			thermal-sensors = <&tsens3 11>;

			trips {
				trip-point0 {
					temperature = <105000>;
					hysteresis = <10000>;
					type = "passive";
				};

				trip-point1 {
					temperature = <115000>;
					hysteresis = <10000>;
					type = "passive";
				};
			};
		};

		audhvx-2-1-thermal {
			polling-delay-passive = <0>;
			polling-delay = <0>;

			thermal-sensors = <&tsens3 12>;

			trips {
				trip-point0 {
					temperature = <105000>;
					hysteresis = <10000>;
					type = "passive";
				};

				trip-point1 {
					temperature = <115000>;
					hysteresis = <10000>;
					type = "passive";
				};
			};
		};

		audhmx-2-1-thermal {
			polling-delay-passive = <0>;
			polling-delay = <0>;

			thermal-sensors = <&tsens3 13>;

			trips {
				trip-point0 {
					temperature = <105000>;
					hysteresis = <10000>;
					type = "passive";
				};

				trip-point1 {
					temperature = <115000>;
					hysteresis = <10000>;
					type = "passive";
				};
			};
		};

		pcie-1-thermal {
			polling-delay-passive = <0>;
			polling-delay = <0>;

			thermal-sensors = <&tsens3 15>;

			trips {
				trip-point0 {
					temperature = <105000>;
					hysteresis = <10000>;
					type = "passive";
				};

				trip-point1 {
					temperature = <115000>;
					hysteresis = <10000>;
					type = "passive";
				};
			};
		};

		nsphvx-0-0-thermal {
			polling-delay-passive = <0>;
			polling-delay = <0>;

			thermal-sensors = <&tsens4 0>;

			trips {
				trip-point0 {
					temperature = <105000>;
					hysteresis = <10000>;
					type = "passive";
				};

				trip-point1 {
					temperature = <115000>;
					hysteresis = <10000>;
					type = "passive";
				};
			};
		};

		nsphvx-0-2-thermal {
			polling-delay-passive = <0>;
			polling-delay = <0>;

			thermal-sensors = <&tsens4 1>;

			trips {
				trip-point0 {
					temperature = <105000>;
					hysteresis = <10000>;
					type = "passive";
				};

				trip-point1 {
					temperature = <115000>;
					hysteresis = <10000>;
					type = "passive";
				};
			};
		};

		nsp-0-0-0-thermal {
			polling-delay-passive = <0>;
			polling-delay = <0>;

			thermal-sensors = <&tsens4 2>;

			trips {
				trip-point0 {
					temperature = <105000>;
					hysteresis = <10000>;
					type = "passive";
				};

				trip-point1 {
					temperature = <115000>;
					hysteresis = <10000>;
					type = "passive";
				};
			};
		};

		nsp-0-1-0-thermal {
			polling-delay-passive = <0>;
			polling-delay = <0>;

			thermal-sensors = <&tsens4 3>;

			trips {
				trip-point0 {
					temperature = <105000>;
					hysteresis = <10000>;
					type = "passive";
				};

				trip-point1 {
					temperature = <115000>;
					hysteresis = <10000>;
					type = "passive";
				};
			};
		};

		nsphvx-1-0-thermal {
			polling-delay-passive = <0>;
			polling-delay = <0>;

			thermal-sensors = <&tsens4 4>;

			trips {
				trip-point0 {
					temperature = <105000>;
					hysteresis = <10000>;
					type = "passive";
				};

				trip-point1 {
					temperature = <115000>;
					hysteresis = <10000>;
					type = "passive";
				};
			};
		};

		nsphvx-1-2-thermal {
			polling-delay-passive = <0>;
			polling-delay = <0>;

			thermal-sensors = <&tsens4 5>;

			trips {
				trip-point0 {
					temperature = <105000>;
					hysteresis = <10000>;
					type = "passive";
				};

				trip-point1 {
					temperature = <115000>;
					hysteresis = <10000>;
					type = "passive";
				};
			};
		};

		nsp-1-0-0-thermal {
			polling-delay-passive = <0>;
			polling-delay = <0>;

			thermal-sensors = <&tsens4 6>;

			trips {
				trip-point0 {
					temperature = <105000>;
					hysteresis = <10000>;
					type = "passive";
				};

				trip-point1 {
					temperature = <115000>;
					hysteresis = <10000>;
					type = "passive";
				};
			};
		};

		nsp-1-1-0-thermal {
			polling-delay-passive = <0>;
			polling-delay = <0>;

			thermal-sensors = <&tsens4 7>;

			trips {
				trip-point0 {
					temperature = <105000>;
					hysteresis = <10000>;
					type = "passive";
				};

				trip-point1 {
					temperature = <115000>;
					hysteresis = <10000>;
					type = "passive";
				};
			};
		};

		nsphvx-2-0-thermal {
			polling-delay-passive = <0>;
			polling-delay = <0>;

			thermal-sensors = <&tsens4 8>;

			trips {
				trip-point0 {
					temperature = <105000>;
					hysteresis = <10000>;
					type = "passive";
				};

				trip-point1 {
					temperature = <115000>;
					hysteresis = <10000>;
					type = "passive";
				};
			};
		};

		nsphvx-2-2-thermal {
			polling-delay-passive = <0>;
			polling-delay = <0>;

			thermal-sensors = <&tsens4 9>;

			trips {
				trip-point0 {
					temperature = <105000>;
					hysteresis = <10000>;
					type = "passive";
				};

				trip-point1 {
					temperature = <115000>;
					hysteresis = <10000>;
					type = "passive";
				};
			};
		};

		nsp-2-0-0-thermal {
			polling-delay-passive = <0>;
			polling-delay = <0>;

			thermal-sensors = <&tsens4 10>;

			trips {
				trip-point0 {
					temperature = <105000>;
					hysteresis = <10000>;
					type = "passive";
				};

				trip-point1 {
					temperature = <115000>;
					hysteresis = <10000>;
					type = "passive";
				};
			};
		};

		nsp-2-1-0-thermal {
			polling-delay-passive = <0>;
			polling-delay = <0>;

			thermal-sensors = <&tsens4 11>;

			trips {
				trip-point0 {
					temperature = <105000>;
					hysteresis = <10000>;
					type = "passive";
				};

				trip-point1 {
					temperature = <115000>;
					hysteresis = <10000>;
					type = "passive";
				};
			};
		};

		nsphvx-3-0-thermal {
			polling-delay-passive = <0>;
			polling-delay = <0>;

			thermal-sensors = <&tsens4 12>;

			trips {
				trip-point0 {
					temperature = <105000>;
					hysteresis = <10000>;
					type = "passive";
				};

				trip-point1 {
					temperature = <115000>;
					hysteresis = <10000>;
					type = "passive";
				};
			};
		};

		nsphvx-3-2-thermal {
			polling-delay-passive = <0>;
			polling-delay = <0>;

			thermal-sensors = <&tsens4 13>;

			trips {
				trip-point0 {
					temperature = <105000>;
					hysteresis = <10000>;
					type = "passive";
				};

				trip-point1 {
					temperature = <115000>;
					hysteresis = <10000>;
					type = "passive";
				};
			};
		};

		nsp-3-0-0-thermal {
			polling-delay-passive = <0>;
			polling-delay = <0>;

			thermal-sensors = <&tsens4 14>;

			trips {
				trip-point0 {
					temperature = <105000>;
					hysteresis = <10000>;
					type = "passive";
				};

				trip-point1 {
					temperature = <115000>;
					hysteresis = <10000>;
					type = "passive";
				};
			};
		};

		nsp-3-1-0-thermal {
			polling-delay-passive = <0>;
			polling-delay = <0>;

			thermal-sensors = <&tsens4 15>;

			trips {
				trip-point0 {
					temperature = <105000>;
					hysteresis = <10000>;
					type = "passive";
				};

				trip-point1 {
					temperature = <115000>;
					hysteresis = <10000>;
					type = "passive";
				};
			};
		};

		nsphvx-0-1-thermal {
			polling-delay-passive = <0>;
			polling-delay = <0>;

			thermal-sensors = <&tsens5 0>;

			trips {
				trip-point0 {
					temperature = <105000>;
					hysteresis = <10000>;
					type = "passive";
				};

				trip-point1 {
					temperature = <115000>;
					hysteresis = <10000>;
					type = "passive";
				};
			};
		};

		nsphvx-0-3-thermal {
			polling-delay-passive = <0>;
			polling-delay = <0>;

			thermal-sensors = <&tsens5 1>;

			trips {
				trip-point0 {
					temperature = <105000>;
					hysteresis = <10000>;
					type = "passive";
				};

				trip-point1 {
					temperature = <115000>;
					hysteresis = <10000>;
					type = "passive";
				};
			};
		};

		nsp-0-0-1-thermal {
			polling-delay-passive = <0>;
			polling-delay = <0>;

			thermal-sensors = <&tsens5 2>;

			trips {
				trip-point0 {
					temperature = <105000>;
					hysteresis = <10000>;
					type = "passive";
				};

				trip-point1 {
					temperature = <115000>;
					hysteresis = <10000>;
					type = "passive";
				};
			};
		};

		nsp-0-1-1-thermal {
			polling-delay-passive = <0>;
			polling-delay = <0>;

			thermal-sensors = <&tsens5 3>;

			trips {
				trip-point0 {
					temperature = <105000>;
					hysteresis = <10000>;
					type = "passive";
				};

				trip-point1 {
					temperature = <115000>;
					hysteresis = <10000>;
					type = "passive";
				};
			};
		};

		nsphvx-1-1-thermal {
			polling-delay-passive = <0>;
			polling-delay = <0>;

			thermal-sensors = <&tsens5 4>;

			trips {
				trip-point0 {
					temperature = <105000>;
					hysteresis = <10000>;
					type = "passive";
				};

				trip-point1 {
					temperature = <115000>;
					hysteresis = <10000>;
					type = "passive";
				};
			};
		};

		nsphvx-1-3-thermal {
			polling-delay-passive = <0>;
			polling-delay = <0>;

			thermal-sensors = <&tsens5 5>;

			trips {
				trip-point0 {
					temperature = <105000>;
					hysteresis = <10000>;
					type = "passive";
				};

				trip-point1 {
					temperature = <115000>;
					hysteresis = <10000>;
					type = "passive";
				};
			};
		};

		nsp-1-0-1-thermal {
			polling-delay-passive = <0>;
			polling-delay = <0>;

			thermal-sensors = <&tsens5 6>;

			trips {
				trip-point0 {
					temperature = <105000>;
					hysteresis = <10000>;
					type = "passive";
				};

				trip-point1 {
					temperature = <115000>;
					hysteresis = <10000>;
					type = "passive";
				};
			};
		};

		nsp-1-1-1-thermal {
			polling-delay-passive = <0>;
			polling-delay = <0>;

			thermal-sensors = <&tsens5 7>;

			trips {
				trip-point0 {
					temperature = <105000>;
					hysteresis = <10000>;
					type = "passive";
				};

				trip-point1 {
					temperature = <115000>;
					hysteresis = <10000>;
					type = "passive";
				};
			};
		};

		nsphvx-2-1-thermal {
			polling-delay-passive = <0>;
			polling-delay = <0>;

			thermal-sensors = <&tsens5 8>;

			trips {
				trip-point0 {
					temperature = <105000>;
					hysteresis = <10000>;
					type = "passive";
				};

				trip-point1 {
					temperature = <115000>;
					hysteresis = <10000>;
					type = "passive";
				};
			};
		};

		nsphvx-2-3-thermal {
			polling-delay-passive = <0>;
			polling-delay = <0>;

			thermal-sensors = <&tsens5 9>;

			trips {
				trip-point0 {
					temperature = <105000>;
					hysteresis = <10000>;
					type = "passive";
				};

				trip-point1 {
					temperature = <115000>;
					hysteresis = <10000>;
					type = "passive";
				};
			};
		};

		nsp-2-0-1-thermal {
			polling-delay-passive = <0>;
			polling-delay = <0>;

			thermal-sensors = <&tsens5 10>;

			trips {
				trip-point0 {
					temperature = <105000>;
					hysteresis = <10000>;
					type = "passive";
				};

				trip-point1 {
					temperature = <115000>;
					hysteresis = <10000>;
					type = "passive";
				};
			};
		};

		nsp-2-1-1-thermal {
			polling-delay-passive = <0>;
			polling-delay = <0>;

			thermal-sensors = <&tsens5 11>;

			trips {
				trip-point0 {
					temperature = <105000>;
					hysteresis = <10000>;
					type = "passive";
				};

				trip-point1 {
					temperature = <115000>;
					hysteresis = <10000>;
					type = "passive";
				};
			};
		};

		nsphvx-3-1-thermal {
			polling-delay-passive = <0>;
			polling-delay = <0>;

			thermal-sensors = <&tsens5 12>;

			trips {
				trip-point0 {
					temperature = <105000>;
					hysteresis = <10000>;
					type = "passive";
				};

				trip-point1 {
					temperature = <115000>;
					hysteresis = <10000>;
					type = "passive";
				};
			};
		};

		nsphvx-3-3-thermal {
			polling-delay-passive = <0>;
			polling-delay = <0>;

			thermal-sensors = <&tsens5 13>;

			trips {
				trip-point0 {
					temperature = <105000>;
					hysteresis = <10000>;
					type = "passive";
				};

				trip-point1 {
					temperature = <115000>;
					hysteresis = <10000>;
					type = "passive";
				};
			};
		};

		nsp-3-0-1-thermal {
			polling-delay-passive = <0>;
			polling-delay = <0>;

			thermal-sensors = <&tsens5 14>;

			trips {
				trip-point0 {
					temperature = <105000>;
					hysteresis = <10000>;
					type = "passive";
				};

				trip-point1 {
					temperature = <115000>;
					hysteresis = <10000>;
					type = "passive";
				};
			};
		};

		nsp-3-1-1-thermal {
			polling-delay-passive = <0>;
			polling-delay = <0>;

			thermal-sensors = <&tsens5 15>;

			trips {
				trip-point0 {
					temperature = <105000>;
					hysteresis = <10000>;
					type = "passive";
				};

				trip-point1 {
					temperature = <115000>;
					hysteresis = <10000>;
					type = "passive";
				};
			};
		};

		amux-6-thermal {
			polling-delay-passive = <0>;
			polling-delay = <0>;

			thermal-sensors = <&tsens6 0>;

			trips {
				trip-point0 {
					temperature = <105000>;
					hysteresis = <10000>;
					type = "passive";
				};

				trip-point1 {
					temperature = <115000>;
					hysteresis = <10000>;
					type = "passive";
				};
			};
		};

		gpuss-0-thermal {
			polling-delay-passive = <0>;
			polling-delay = <0>;

			thermal-sensors = <&tsens6 1>;

			trips {
				trip-point0 {
					temperature = <105000>;
					hysteresis = <10000>;
					type = "passive";
				};

				trip-point1 {
					temperature = <115000>;
					hysteresis = <10000>;
					type = "passive";
				};
			};
		};

		gpuss-1-thermal {
			polling-delay-passive = <0>;
			polling-delay = <0>;

			thermal-sensors = <&tsens6 2>;

			trips {
				trip-point0 {
					temperature = <105000>;
					hysteresis = <10000>;
					type = "passive";
				};

				trip-point1 {
					temperature = <115000>;
					hysteresis = <10000>;
					type = "passive";
				};
			};
		};

		gpuss-2-thermal {
			polling-delay-passive = <0>;
			polling-delay = <0>;

			thermal-sensors = <&tsens6 3>;

			trips {
				trip-point0 {
					temperature = <105000>;
					hysteresis = <10000>;
					type = "passive";
				};

				trip-point1 {
					temperature = <115000>;
					hysteresis = <10000>;
					type = "passive";
				};
			};
		};

		gpu-0-0-0-thermal {
			polling-delay-passive = <0>;
			polling-delay = <0>;

			thermal-sensors = <&tsens6 4>;

			trips {
				trip-point0 {
					temperature = <105000>;
					hysteresis = <10000>;
					type = "passive";
				};

				trip-point1 {
					temperature = <115000>;
					hysteresis = <10000>;
					type = "passive";
				};
			};
		};

		gpuss-1-0-thermal {
			polling-delay-passive = <0>;
			polling-delay = <0>;

			thermal-sensors = <&tsens6 5>;

			trips {
				trip-point0 {
					temperature = <105000>;
					hysteresis = <10000>;
					type = "passive";
				};

				trip-point1 {
					temperature = <115000>;
					hysteresis = <10000>;
					type = "passive";
				};
			};
		};

		gpuss-1-1-thermal {
			polling-delay-passive = <0>;
			polling-delay = <0>;

			thermal-sensors = <&tsens6 6>;

			trips {
				trip-point0 {
					temperature = <105000>;
					hysteresis = <10000>;
					type = "passive";
				};

				trip-point1 {
					temperature = <115000>;
					hysteresis = <10000>;
					type = "passive";
				};
			};
		};

		cv-0-thermal {
			polling-delay-passive = <0>;
			polling-delay = <0>;

			thermal-sensors = <&tsens6 7>;

			trips {
				trip-point0 {
					temperature = <105000>;
					hysteresis = <10000>;
					type = "passive";
				};

				trip-point1 {
					temperature = <115000>;
					hysteresis = <10000>;
					type = "passive";
				};
			};
		};

		video-0-thermal {
			polling-delay-passive = <0>;
			polling-delay = <0>;

			thermal-sensors = <&tsens6 8>;

			trips {
				trip-point0 {
					temperature = <105000>;
					hysteresis = <10000>;
					type = "passive";
				};

				trip-point1 {
					temperature = <115000>;
					hysteresis = <10000>;
					type = "passive";
				};
			};
		};

		camera-1-thermal {
			polling-delay-passive = <0>;
			polling-delay = <0>;

			thermal-sensors = <&tsens6 9>;

			trips {
				trip-point0 {
					temperature = <105000>;
					hysteresis = <10000>;
					type = "passive";
				};

				trip-point1 {
					temperature = <115000>;
					hysteresis = <10000>;
					type = "passive";
				};
			};
		};

		ddr-2-0-thermal {
			polling-delay-passive = <0>;
			polling-delay = <0>;

			thermal-sensors = <&tsens6 10>;

			trips {
				trip-point0 {
					temperature = <105000>;
					hysteresis = <10000>;
					type = "passive";
				};

				trip-point1 {
					temperature = <115000>;
					hysteresis = <10000>;
					type = "passive";
				};
			};
		};

		ddr-3-0-thermal {
			polling-delay-passive = <0>;
			polling-delay = <0>;

			thermal-sensors = <&tsens6 11>;

			trips {
				trip-point0 {
					temperature = <105000>;
					hysteresis = <10000>;
					type = "passive";
				};

				trip-point1 {
					temperature = <115000>;
					hysteresis = <10000>;
					type = "passive";
				};
			};
		};

		gpuss-0-1-1-thermal {
			polling-delay-passive = <0>;
			polling-delay = <0>;

			thermal-sensors = <&tsens6 12>;

			trips {
				trip-point0 {
					temperature = <105000>;
					hysteresis = <10000>;
					type = "passive";
				};

				trip-point1 {
					temperature = <115000>;
					hysteresis = <10000>;
					type = "passive";
				};
			};
		};

		gpuss-1-1-1-thermal {
			polling-delay-passive = <0>;
			polling-delay = <0>;

			thermal-sensors = <&tsens6 13>;

			trips {
				trip-point0 {
					temperature = <105000>;
					hysteresis = <10000>;
					type = "passive";
				};

				trip-point1 {
					temperature = <115000>;
					hysteresis = <10000>;
					type = "passive";
				};
			};
		};

		gpuss-2-1-1-thermal {
			polling-delay-passive = <0>;
			polling-delay = <0>;

			thermal-sensors = <&tsens6 14>;

			trips {
				trip-point0 {
					temperature = <105000>;
					hysteresis = <10000>;
					type = "passive";
				};

				trip-point1 {
					temperature = <115000>;
					hysteresis = <10000>;
					type = "passive";
				};
			};
		};

		gpu-0-1-1-thermal {
			polling-delay-passive = <0>;
			polling-delay = <0>;

			thermal-sensors = <&tsens6 15>;

			trips {
				trip-point0 {
					temperature = <105000>;
					hysteresis = <10000>;
					type = "passive";
				};

				trip-point1 {
					temperature = <115000>;
					hysteresis = <10000>;
					type = "passive";
				};
			};
		};

		amux-7-thermal {
			polling-delay-passive = <0>;
			polling-delay = <0>;

			thermal-sensors = <&tsens7 0>;

			trips {
				trip-point0 {
					temperature = <105000>;
					hysteresis = <10000>;
					type = "passive";
				};

				trip-point1 {
					temperature = <115000>;
					hysteresis = <10000>;
					type = "passive";
				};
			};
		};

		gpuss-0-1-0-thermal {
			polling-delay-passive = <0>;
			polling-delay = <0>;

			thermal-sensors = <&tsens7 1>;

			trips {
				trip-point0 {
					temperature = <105000>;
					hysteresis = <10000>;
					type = "passive";
				};

				trip-point1 {
					temperature = <115000>;
					hysteresis = <10000>;
					type = "passive";
				};
			};
		};

		gpuss-1-1-0-thermal {
			polling-delay-passive = <0>;
			polling-delay = <0>;

			thermal-sensors = <&tsens7 2>;

			trips {
				trip-point0 {
					temperature = <105000>;
					hysteresis = <10000>;
					type = "passive";
				};

				trip-point1 {
					temperature = <115000>;
					hysteresis = <10000>;
					type = "passive";
				};
			};
		};

		gpuss-2-1-0-thermal {
			polling-delay-passive = <0>;
			polling-delay = <0>;

			thermal-sensors = <&tsens7 3>;

			trips {
				trip-point0 {
					temperature = <105000>;
					hysteresis = <10000>;
					type = "passive";
				};

				trip-point1 {
					temperature = <115000>;
					hysteresis = <10000>;
					type = "passive";
				};
			};
		};

		gpu-0-1-0-thermal {
			polling-delay-passive = <0>;
			polling-delay = <0>;

			thermal-sensors = <&tsens7 4>;

			trips {
				trip-point0 {
					temperature = <105000>;
					hysteresis = <10000>;
					type = "passive";
				};

				trip-point1 {
					temperature = <115000>;
					hysteresis = <10000>;
					type = "passive";
				};
			};
		};

		gpuss-1-2-thermal {
			polling-delay-passive = <0>;
			polling-delay = <0>;

			thermal-sensors = <&tsens7 5>;

			trips {
				trip-point0 {
					temperature = <105000>;
					hysteresis = <10000>;
					type = "passive";
				};

				trip-point1 {
					temperature = <115000>;
					hysteresis = <10000>;
					type = "passive";
				};
			};
		};

		gpu-1-0-thermal {
			polling-delay-passive = <0>;
			polling-delay = <0>;

			thermal-sensors = <&tsens7 6>;

			trips {
				trip-point0 {
					temperature = <105000>;
					hysteresis = <10000>;
					type = "passive";
				};

				trip-point1 {
					temperature = <115000>;
					hysteresis = <10000>;
					type = "passive";
				};
			};
		};

		cv-1-thermal {
			polling-delay-passive = <0>;
			polling-delay = <0>;

			thermal-sensors = <&tsens7 7>;

			trips {
				trip-point0 {
					temperature = <105000>;
					hysteresis = <10000>;
					type = "passive";
				};

				trip-point1 {
					temperature = <115000>;
					hysteresis = <10000>;
					type = "passive";
				};
			};
		};

		video-1-thermal {
			polling-delay-passive = <0>;
			polling-delay = <0>;

			thermal-sensors = <&tsens7 8>;

			trips {
				trip-point0 {
					temperature = <105000>;
					hysteresis = <10000>;
					type = "passive";
				};

				trip-point1 {
					temperature = <115000>;
					hysteresis = <10000>;
					type = "passive";
				};
			};
		};

		camera-2-thermal {
			polling-delay-passive = <0>;
			polling-delay = <0>;

			thermal-sensors = <&tsens7 9>;

			trips {
				trip-point0 {
					temperature = <105000>;
					hysteresis = <10000>;
					type = "passive";
				};

				trip-point1 {
					temperature = <115000>;
					hysteresis = <10000>;
					type = "passive";
				};
			};
		};

		ddr-2-1-thermal {
			polling-delay-passive = <0>;
			polling-delay = <0>;

			thermal-sensors = <&tsens7 10>;

			trips {
				trip-point0 {
					temperature = <105000>;
					hysteresis = <10000>;
					type = "passive";
				};

				trip-point1 {
					temperature = <115000>;
					hysteresis = <10000>;
					type = "passive";
				};
			};
		};

		ddr-3-1-thermal {
			polling-delay-passive = <0>;
			polling-delay = <0>;

			thermal-sensors = <&tsens7 11>;

			trips {
				trip-point0 {
					temperature = <105000>;
					hysteresis = <10000>;
					type = "passive";
				};

				trip-point1 {
					temperature = <115000>;
					hysteresis = <10000>;
					type = "passive";
				};
			};
		};

		gpuss-0-1-thermal {
			polling-delay-passive = <0>;
			polling-delay = <0>;

			thermal-sensors = <&tsens7 12>;

			trips {
				trip-point0 {
					temperature = <105000>;
					hysteresis = <10000>;
					type = "passive";
				};

				trip-point1 {
					temperature = <115000>;
					hysteresis = <10000>;
					type = "passive";
				};
			};
		};

		gpuss-1-0-1-thermal {
			polling-delay-passive = <0>;
			polling-delay = <0>;

			thermal-sensors = <&tsens7 13>;

			trips {
				trip-point0 {
					temperature = <105000>;
					hysteresis = <10000>;
					type = "passive";
				};

				trip-point1 {
					temperature = <115000>;
					hysteresis = <10000>;
					type = "passive";
				};
			};
		};

		gpuss-2-0-1-thermal {
			polling-delay-passive = <0>;
			polling-delay = <0>;

			thermal-sensors = <&tsens7 14>;

			trips {
				trip-point0 {
					temperature = <105000>;
					hysteresis = <10000>;
					type = "passive";
				};

				trip-point1 {
					temperature = <115000>;
					hysteresis = <10000>;
					type = "passive";
				};
			};
		};

		gpu-0-0-1-thermal {
			polling-delay-passive = <0>;
			polling-delay = <0>;

			thermal-sensors = <&tsens7 15>;

			trips {
				trip-point0 {
					temperature = <105000>;
					hysteresis = <10000>;
					type = "passive";
				};

				trip-point1 {
					temperature = <115000>;
					hysteresis = <10000>;
					type = "passive";
				};
			};
		};
	};
};
